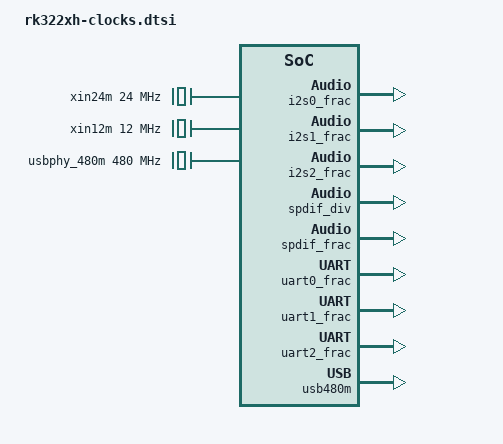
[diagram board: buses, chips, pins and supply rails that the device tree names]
/*
 * Copyright (C) 2014-2015 ROCKCHIP, Inc.
 *
 * This program is free software; you can redistribute it and/or modify
 * it under the terms of the GNU General Public License as published by
 * the Free Software Foundation; either version 2 of the License, or
 * (at your option) any later version.
 *
 * This program is distributed in the hope that it will be useful,
 * but WITHOUT ANY WARRANTY; without even the implied warranty of
 * MERCHANTABILITY or FITNESS FOR A PARTICULAR PURPOSE.  See the
 * GNU General Public License for more details.
 */
#include <dt-bindings/clock/rockchip,rk322xh.h>

/{
	clocks {
		compatible = "rockchip,rk-clocks";
		rockchip,grf = <&grf>;
		#address-cells = <2>;
		#size-cells = <2>;
		ranges;

		fixed_rate_cons {
			compatible = "rockchip,rk-fixed-rate-cons";

			xin24m: xin24m {
				compatible = "rockchip,rk-fixed-clock";
				clock-output-names = "xin24m";
				clock-frequency = <24000000>;
				#clock-cells = <0>;
			};

			xin12m: xin12m {
				compatible = "rockchip,rk-fixed-clock";
				clocks = <&xin24m>;
				clock-output-names = "xin12m";
				clock-frequency = <12000000>;
				#clock-cells = <0>;
			};

			hdmiphy_out: hdmiphy_out {
				compatible = "rockchip,rk-fixed-clock";
				clock-output-names = "hdmiphy_out";
				clock-frequency = <594000000>;
				#clock-cells = <0>;
			};

			usbphy_480m: usbphy_480m {
				compatible = "rockchip,rk-fixed-clock";
				clock-output-names = "usbphy_480m";
				clock-frequency = <480000000>;
				#clock-cells = <0>;
			};

			jtag_clkin: jtag_clkin {
				compatible = "rockchip,rk-fixed-clock";
				clock-output-names = "jtag_clkin";
				clock-frequency = <0>;
				#clock-cells = <0>;
			};

			dummy: dummy {
				compatible = "rockchip,rk-fixed-clock";
				clock-output-names = "dummy";
				clock-frequency = <0>;
				#clock-cells = <0>;
			};

			gmac_clkin: gmac_clkin {
				compatible = "rockchip,rk-fixed-clock";
				clock-output-names = "gmac_clkin";
				clock-frequency = <0>;
				#clock-cells = <0>;
			};

			phy_50m_out: phy_50m_out {
				compatible = "rockchip,rk-fixed-clock";
				clock-output-names = "phy_50m_out";
				clock-frequency = <0>;
				#clock-cells = <0>;
			};

			phy_rx_out: phy_rx_out {
				compatible = "rockchip,rk-fixed-clock";
				clock-output-names = "phy_rx_out";
				clock-frequency = <0>;
				#clock-cells = <0>;
			};

			phy_tx_out: phy_tx_out {
				compatible = "rockchip,rk-fixed-clock";
				clock-output-names = "phy_tx_out";
				clock-frequency = <0>;
				#clock-cells = <0>;
			};

			ext_gpio3a2: ext_gpio3a2 {
				compatible = "rockchip,rk-fixed-clock";
				clock-output-names = "ext_gpio3a2";
				clock-frequency = <0>;
				#clock-cells = <0>;
			};

			i2s1_clkin: i2s1_clkin {
				compatible = "rockchip,rk-fixed-clock";
				clock-output-names = "i2s1_clkin";
				clock-frequency = <0>;
				#clock-cells = <0>;
			};

			i2s2_clkin: i2s2_clkin {
				compatible = "rockchip,rk-fixed-clock";
				clock-output-names = "i2s2_clkin";
				clock-frequency = <0>;
				#clock-cells = <0>;
			};

		};

		fixed_factor_cons {
			compatible = "rockchip,rk-fixed-factor-cons";

			hclk_rkvdec: hclk_rkvdec {
				compatible = "rockchip,rk-fixed-factor-clock";
				clocks = <&aclk_rkvdec>;
				clock-output-names = "hclk_rkvdec";
				clock-div = <4>;
				clock-mult = <1>;
				#clock-cells = <0>;
			};

			hclk_vpu: hclk_vpu {
				compatible = "rockchip,rk-fixed-factor-clock";
				clocks = <&aclk_vpu>;
				clock-output-names = "hclk_vpu";
				clock-div = <4>;
				clock-mult = <1>;
				#clock-cells = <0>;
			};

			hclk_rkvenc: hclk_rkvenc {
				compatible = "rockchip,rk-fixed-factor-clock";
				clocks = <&aclk_rkvenc>;
				clock-output-names = "hclk_rkvenc";
				clock-div = <4>;
				clock-mult = <1>;
				#clock-cells = <0>;
			};

		};

		clock_regs {
			compatible = "rockchip,rk-clock-regs";
			#address-cells = <1>;
			#size-cells = <1>;
			ranges = <0x0 0x0 0xff440000 0x1000>;
			reg = <0x0 0xff440000 0x0 0x1000>;

			/* PLL control regs */
			pll_cons {
				compatible = "rockchip,rk-pll-cons";
				#address-cells = <1>;
				#size-cells = <1>;
				ranges;

				clk_apll: pll-clk@0000 {
					compatible = "rockchip,rk3188-pll-clk";
					reg = <0x0000 0x10>;
					mode-reg = <0x80 0>;
					status-reg = <0x04 10>;
					clocks = <&xin24m>;
					clock-output-names = "clk_apll";
					rockchip,pll-type = <CLK_PLL_312XPLUS>;
					#clock-cells = <0>;
					#clock-init-cells = <1>;
				};

				clk_dpll: pll-clk@0020 {
					compatible = "rockchip,rk3188-pll-clk";
					reg = <0x0020 0x10>;
					mode-reg = <0x80 4>;
					status-reg = <0x24 10>;
					clocks = <&xin24m>;
					clock-output-names = "clk_dpll";
					rockchip,pll-type = <CLK_PLL_3036PLUS_AUTO>;
					#clock-cells = <0>;
				};

				clk_cpll: pll-clk@0040 {
					compatible = "rockchip,rk3188-pll-clk";
					reg = <0x0040 0x1c>;
					mode-reg = <0x80 8>;
					status-reg = <0x44 10>;
					clocks = <&xin24m>;
					clock-output-names = "clk_cpll";
					rockchip,pll-type = <CLK_PLL_3036PLUS_AUTO>;
					#clock-cells = <0>;
					#clock-init-cells = <1>;
				};

				clk_gpll: pll-clk@0060 {
					compatible = "rockchip,rk3188-pll-clk";
					reg = <0x0060 0x1c>;
					mode-reg = <0x80 12>;
					status-reg = <0x64 10>;
					clocks = <&xin24m>;
					clock-output-names = "clk_gpll";
					rockchip,pll-type = <CLK_PLL_312XPLUS>;
					#clock-cells = <0>;
					#clock-init-cells = <1>;
				};

				clk_npll: pll-clk@00a0 {
					compatible = "rockchip,rk3188-pll-clk";
					reg = <0x00a0 0x10>;
					mode-reg = <0x80 1>;
					status-reg = <0xa4 10>;
					clocks = <&xin24m>;
					clock-output-names = "clk_npll";
					rockchip,pll-type = <CLK_PLL_322XH_APLL>;
					#clock-cells = <0>;
					#clock-init-cells = <1>;
				};
			};

			/* Select control regs */
			clk_sel_cons {
				compatible = "rockchip,rk-sel-cons";
				#address-cells = <1>;
				#size-cells = <1>;
				ranges;

				clk_sel_con0: sel-con@0100 {
					compatible = "rockchip,rk3188-selcon";
					reg = <0x0100 0x4>;
					#address-cells = <1>;
					#size-cells = <1>;

					clk_core_div: clk_core_div {
						compatible = "rockchip,rk3188-div-con";
						rockchip,bits = <0 5>;
						clocks = <&clk_core>;
						clock-output-names = "clk_core";
						rockchip,div-type = <CLK_DIVIDER_PLUS_ONE>;
						#clock-cells = <0>;
						rockchip,clkops-idx = <CLKOPS_RATE_CORE>;
						rockchip,flags = <(CLK_GET_RATE_NOCACHE |
									CLK_SET_RATE_NO_REPARENT)>;
					};

					/* 5 reserved */

					clk_core: clk_core_mux {
						compatible = "rockchip,rk3188-mux-con";
						rockchip,bits = <6 2>;
						clocks = <&clk_apll>, <&clk_gpll>, <&clk_dpll>, <&clk_npll>;
						clock-output-names = "clk_core";
						#clock-cells = <0>;
						#clock-init-cells = <1>;
					};

					aclk_bus: aclk_bus_div {
						compatible = "rockchip,rk3188-div-con";
						rockchip,bits = <8 5>;
						clocks = <&aclk_bus_mux>;
						clock-output-names = "aclk_bus";
						rockchip,div-type = <CLK_DIVIDER_PLUS_ONE>;
						#clock-cells = <0>;
						#clock-init-cells = <1>;
						rockchip,clkops-idx = <CLKOPS_RATE_MUX_DIV>;
						rockchip,flags = <CLK_SET_RATE_PARENT_IN_ORDER>;
					};

					aclk_bus_mux: aclk_bus_mux {
						compatible = "rockchip,rk3188-mux-con";
						rockchip,bits = <13 2>;
						clocks = <&clk_cpll>, <&clk_gpll>, <&dummy>;
						clock-output-names = "aclk_bus";
						#clock-cells = <0>;
						#clock-init-cells = <1>;
					};

					/* 15 reserved */
				};

				clk_sel_con1: sel-con@0104 {
					compatible = "rockchip,rk3188-selcon";
					reg = <0x0104 0x4>;
					#address-cells = <1>;
					#size-cells = <1>;

					pclk_dbg:  pclk_dbg_div {
						compatible = "rockchip,rk3188-div-con";
						rockchip,bits = <0 4>;
						clocks = <&clk_core>;
						clock-output-names = "pclk_dbg";
						rockchip,div-type = <CLK_DIVIDER_PLUS_ONE>;
						#clock-cells = <0>;
						rockchip,clkops-idx = <CLKOPS_RATE_CORE_CHILD>;
					};

					aclk_core: aclk_core_div {
						compatible = "rockchip,rk3188-div-con";
						rockchip,bits = <4 3>;
						clocks = <&clk_core>;
						clock-output-names = "aclk_core";
						rockchip,div-type = <CLK_DIVIDER_PLUS_ONE>;
						#clock-cells = <0>;
						rockchip,clkops-idx = <CLKOPS_RATE_CORE_CHILD>;
					};

					/* 7 reserved */

					hclk_bus: hclk_bus_div {
						compatible = "rockchip,rk3188-div-con";
						rockchip,bits = <8 2>;
						clocks = <&aclk_bus>;
						clock-output-names = "hclk_bus";
						rockchip,div-type = <CLK_DIVIDER_PLUS_ONE>;
						#clock-cells = <0>;
						#clock-init-cells = <1>;
					};

					/* 11:10 reserved */

					pclk_bus: pclk_bus_div {
						compatible = "rockchip,rk3188-div-con";
						rockchip,bits = <12 3>;
						clocks = <&aclk_bus>;
						clock-output-names = "pclk_bus";
						rockchip,div-type = <CLK_DIVIDER_PLUS_ONE>;
						#clock-cells = <0>;
						#clock-init-cells = <1>;
					};

					/* 15 reserved */
				};

				clk_sel_con2: sel-con@0108 {
					compatible = "rockchip,rk3188-selcon";
					reg = <0x0108 0x4>;
					#address-cells = <1>;
					#size-cells = <1>;

					testclk_div: testclk_div {
						compatible = "rockchip,rk3188-div-con";
						rockchip,bits = <0 5>;
						clocks = <&testclk>;
						clock-output-names = "testclk";
						rockchip,div-type = <CLK_DIVIDER_PLUS_ONE>;
						#clock-cells = <0>;
						#clock-init-cells = <1>;
						rockchip,clkops-idx = <CLKOPS_RATE_MUX_DIV>;
					};

					/* 7:5 reserved */

					clk_24m: clk_24m_div {
						compatible = "rockchip,rk3188-div-con";
						rockchip,bits = <8 5>;
						clocks = <&xin24m>;
						clock-output-names = "clk_24m";
						rockchip,div-type = <CLK_DIVIDER_PLUS_ONE>;
						#clock-cells = <0>;
						#clock-init-cells = <1>;
					};

					/* 15:13: reserved */
				};

				clk_sel_con3: sel-con@010c {
					compatible = "rockchip,rk3188-selcon";
					reg = <0x010c 0x4>;
					#address-cells = <1>;
					#size-cells = <1>;

					clk_ddr_div: clk_ddr_div {
						compatible = "rockchip,rk3188-div-con";
						rockchip,bits = <0 3>;
						clocks = <&clk_ddr>;
						clock-output-names = "clk_ddr";
						rockchip,div-type = <CLK_DIVIDER_USER_DEFINE>;
						rockchip,div-relations =
								<0x0 1
								 0x1 2
								 0x3 4>;
						#clock-cells = <0>;
						rockchip,flags = <(CLK_GET_RATE_NOCACHE |
									CLK_SET_RATE_NO_REPARENT)>;
						rockchip,clkops-idx = <CLKOPS_RATE_DDR_DIV2>;
					};

					/* 7:3 reserved */

					clk_ddr: clk_ddr_pll_mux {
						compatible = "rockchip,rk3188-mux-con";
						rockchip,bits = <8 2>;
						clocks = <&clk_dpll>, <&clk_apll>, <&clk_cpll>;
						clock-output-names = "clk_ddr";
						#clock-cells = <0>;
					};

					/* 15:10 reserved */
				};

				clk_sel_con4: sel-con@0110 {
					compatible = "rockchip,rk3188-selcon";
					reg = <0x0110 0x4>;
					#address-cells = <1>;
					#size-cells = <1>;

					clk_otp_div: clk_otp_div {
						compatible = "rockchip,rk3188-div-con";
						rockchip,bits = <0 6>;
						clocks = <&clk_otp>;
						clock-output-names = "clk_otp";
						rockchip,div-type = <CLK_DIVIDER_PLUS_ONE>;
						#clock-cells = <0>;
						#clock-init-cells = <1>;
						rockchip,clkops-idx = <CLKOPS_RATE_MUX_DIV>;
						rockchip,flags = <CLK_SET_RATE_PARENT_IN_ORDER>;
					};

					clk_otp: clk_otp_mux {
						compatible = "rockchip,rk3188-mux-con";
						rockchip,bits = <6 2>;
						clocks = <&clk_cpll>, <&clk_gpll>, <&xin24m>;
						clock-output-names = "clk_otp";
						#clock-cells = <0>;
						#clock-init-cells = <1>;
					};

					pclk_ddr_div: pclk_ddr_div {
						compatible = "rockchip,rk3188-div-con";
						rockchip,bits = <8 5>;
						clocks = <&pclk_ddr>;
						clock-output-names = "pclk_ddr";
						rockchip,div-type = <CLK_DIVIDER_PLUS_ONE>;
						#clock-cells = <0>;
						#clock-init-cells = <1>;
						rockchip,clkops-idx = <CLKOPS_RATE_MUX_DIV>;
						rockchip,flags = <CLK_SET_RATE_PARENT_IN_ORDER>;
					};

					pclk_ddr: pclk_ddr_mux {
						compatible = "rockchip,rk3188-mux-con";
						rockchip,bits = <13 2>;
						clocks = <&clk_cpll>, <&clk_gpll>, <&dummy>;
						clock-output-names = "pclk_ddr";
						#clock-cells = <0>;
						#clock-init-cells = <1>;
					};

					/* 15 reserved */
				};

				clk_sel_con5: sel-con@0114 {
					compatible = "rockchip,rk3188-selcon";
					reg = <0x0114 0x4>;
					#address-cells = <1>;
					#size-cells = <1>;

					/* 7:0 reserved */

					clk_efuse_div: clk_efuse_div {
						compatible = "rockchip,rk3188-div-con";
						rockchip,bits = <8 5>;
						clocks = <&clk_efuse>;
						clock-output-names = "clk_efuse";
						rockchip,div-type = <CLK_DIVIDER_PLUS_ONE>;
						#clock-cells = <0>;
						#clock-init-cells = <1>;
						rockchip,clkops-idx = <CLKOPS_RATE_MUX_DIV>;
						rockchip,flags = <CLK_SET_RATE_PARENT_IN_ORDER>;
					};

					/* 14:13 reserved */

					clk_efuse: clk_efuse_mux {
						compatible = "rockchip,rk3188-mux-con";
						rockchip,bits = <14 2>;
						clocks = <&clk_cpll>, <&clk_gpll>, <&xin24m>;
						clock-output-names = "clk_efuse";
						#clock-cells = <0>;
						#clock-init-cells = <1>;
					};
				};

				clk_sel_con6: sel-con@0118 {
					compatible = "rockchip,rk3188-selcon";
					reg = <0x0118 0x4>;
					#address-cells = <1>;
					#size-cells = <1>;

					clk_i2s0_pll_div: clk_i2s0_pll_div {
						compatible = "rockchip,rk3188-div-con";
						rockchip,bits = <0 7>;
						clocks = <&clk_i2s0_pll>;
						clock-output-names = "clk_i2s0_pll";
						rockchip,div-type = <CLK_DIVIDER_PLUS_ONE>;
						#clock-cells = <0>;
						rockchip,clkops-idx =
							<CLKOPS_RATE_MUX_DIV>;
						rockchip,flags = <(CLK_SET_RATE_NO_REPARENT | CLK_SET_RATE_PARENT_IN_ORDER)>;
					};

					/* 7: reserved */

					clk_i2s0: clk_i2s0_mux {
						compatible = "rockchip,rk3188-mux-con";
						rockchip,bits = <8 2>;
						clocks = <&clk_i2s0_pll_div>, <&i2s0_frac>, <&xin12m>, <&xin12m>;
						clock-output-names = "clk_i2s0";
						#clock-cells = <0>;
						rockchip,clkops-idx =
							<CLKOPS_RATE_RK3288_I2S>;
						rockchip,flags = <CLK_SET_RATE_PARENT>;
					};

					/* 14:10: reserved */

					clk_i2s0_pll: i2s0_pll_mux {
						compatible = "rockchip,rk3188-mux-con";
						rockchip,bits = <15 1>;
						clocks = <&clk_cpll>,<&clk_gpll>;
						clock-output-names = "clk_i2s0_pll";
						#clock-cells = <0>;
						#clock-init-cells = <1>;
					};
				};

				clk_sel_con7: sel-con@011c {
					compatible = "rockchip,rk3188-selcon";
					reg = <0x011c 0x4>;
					#address-cells = <1>;
					#size-cells = <1>;

					i2s0_frac: i2s0_frac {
						compatible = "rockchip,rk3188-frac-con";
						clocks = <&clk_i2s0_pll_div>;
						clock-output-names = "i2s0_frac";
						/* numerator	denominator */
						rockchip,bits = <0 32>;
						rockchip,clkops-idx =
							<CLKOPS_RATE_FRAC>;
						#clock-cells = <0>;
					};
				};

				clk_sel_con8: sel-con@0120 {
					compatible = "rockchip,rk3188-selcon";
					reg = <0x0120 0x4>;
					#address-cells = <1>;
					#size-cells = <1>;

					clk_i2s1_pll_div: clk_i2s1_pll_div {
						compatible = "rockchip,rk3188-div-con";
						rockchip,bits = <0 7>;
						clocks = <&clk_i2s1_pll>;
						clock-output-names = "clk_i2s1_pll";
						rockchip,div-type = <CLK_DIVIDER_PLUS_ONE>;
						#clock-cells = <0>;
						rockchip,clkops-idx =
							<CLKOPS_RATE_MUX_DIV>;
						rockchip,flags = <(CLK_SET_RATE_NO_REPARENT | CLK_SET_RATE_PARENT_IN_ORDER)>;
					};

					/* 7: reserved */

					clk_i2s1: clk_i2s1_mux {
						compatible = "rockchip,rk3188-mux-con";
						rockchip,bits = <8 2>;
						clocks = <&clk_i2s1_pll_div>, <&i2s1_frac>, <&i2s1_clkin>, <&xin12m>;
						clock-output-names = "clk_i2s1";
						#clock-cells = <0>;
						rockchip,clkops-idx =
							<CLKOPS_RATE_RK3288_I2S>;
						rockchip,flags = <CLK_SET_RATE_PARENT>;
					};

					/* 11:10: reserved */

					clk_i2s1_out: clk_i2s1_out_mux {
						compatible = "rockchip,rk3188-mux-con";
						rockchip,bits = <12 1>;
						clocks = <&clk_i2s1>, <&xin12m>;
						clock-output-names = "clk_i2s1_out";
						#clock-cells = <0>;
					};

					/* 14:13: reserved */

					clk_i2s1_pll: i2s1_pll_mux {
						compatible = "rockchip,rk3188-mux-con";
						rockchip,bits = <15 1>;
						clocks = <&clk_cpll>,<&clk_gpll>;
						clock-output-names = "clk_i2s1_pll";
						#clock-cells = <0>;
						#clock-init-cells = <1>;
					};
				};

				clk_sel_con9: sel-con@0124 {
					compatible = "rockchip,rk3188-selcon";
					reg = <0x0124 0x4>;
					#address-cells = <1>;
					#size-cells = <1>;

					i2s1_frac: i2s1_frac {
						compatible = "rockchip,rk3188-frac-con";
						clocks = <&clk_i2s1_pll_div>;
						clock-output-names = "i2s1_frac";
						/* numerator	denominator */
						rockchip,bits = <0 32>;
						rockchip,clkops-idx =
							<CLKOPS_RATE_FRAC>;
						#clock-cells = <0>;
					};
				};

				clk_sel_con10: sel-con@0128 {
					compatible = "rockchip,rk3188-selcon";
					reg = <0x0128 0x4>;
					#address-cells = <1>;
					#size-cells = <1>;

					clk_i2s2_pll_div: clk_i2s2_pll_div {
						compatible = "rockchip,rk3188-div-con";
						rockchip,bits = <0 7>;
						clocks = <&clk_i2s2_pll>;
						clock-output-names = "clk_i2s2_pll";
						rockchip,div-type = <CLK_DIVIDER_PLUS_ONE>;
						#clock-cells = <0>;
						rockchip,clkops-idx =
							<CLKOPS_RATE_MUX_DIV>;
						rockchip,flags = <(CLK_SET_RATE_NO_REPARENT | CLK_SET_RATE_PARENT_IN_ORDER)>;
					};

					/* 7: reserved */

					clk_i2s2: clk_i2s2_mux {
						compatible = "rockchip,rk3188-mux-con";
						rockchip,bits = <8 2>;
						clocks = <&clk_i2s2_pll_div>, <&i2s2_frac>, <&i2s2_clkin>, <&xin12m>;
						clock-output-names = "clk_i2s2";
						#clock-cells = <0>;
						rockchip,clkops-idx =
							<CLKOPS_RATE_RK3288_I2S>;
						rockchip,flags = <CLK_SET_RATE_PARENT>;
					};

					/* 11:10: reserved */

					clk_i2s2_out: clk_i2s2_out_mux {
						compatible = "rockchip,rk3188-mux-con";
						rockchip,bits = <12 1>;
						clocks = <&clk_i2s2>, <&xin12m>;
						clock-output-names = "clk_i2s2_out";
						#clock-cells = <0>;
					};

					/* 14:13: reserved */

					clk_i2s2_pll: i2s2_pll_mux {
						compatible = "rockchip,rk3188-mux-con";
						rockchip,bits = <15 1>;
						clocks = <&clk_cpll>,<&clk_gpll>;
						clock-output-names = "clk_i2s2_pll";
						#clock-cells = <0>;
						#clock-init-cells = <1>;
					};
				};

				clk_sel_con11: sel-con@012c {
					compatible = "rockchip,rk3188-selcon";
					reg = <0x012c 0x4>;
					#address-cells = <1>;
					#size-cells = <1>;

					i2s2_frac: i2s2_frac {
						compatible = "rockchip,rk3188-frac-con";
						clocks = <&clk_i2s2_pll_div>;
						clock-output-names = "i2s2_frac";
						/* numerator	denominator */
						rockchip,bits = <0 32>;
						rockchip,clkops-idx =
							<CLKOPS_RATE_FRAC>;
						#clock-cells = <0>;
					};
				};

				clk_sel_con12: sel-con@0130 {
					compatible = "rockchip,rk3188-selcon";
					reg = <0x0130 0x4>;
					#address-cells = <1>;
					#size-cells = <1>;

					spdif_div: spdif_div {
						compatible = "rockchip,rk3188-div-con";
						rockchip,bits = <0 7>;
						clocks = <&clk_spdif_pll>;
						clock-output-names = "clk_spdif_pll";
						rockchip,div-type = <CLK_DIVIDER_PLUS_ONE>;
						#clock-cells = <0>;
						rockchip,clkops-idx =
							<CLKOPS_RATE_MUX_DIV>;
						rockchip,flags = <(CLK_SET_RATE_NO_REPARENT | CLK_SET_RATE_PARENT_IN_ORDER)>;
					};

					/* 7 reserved */

					clk_spdif: spdif_mux {
						compatible = "rockchip,rk3188-mux-con";
						rockchip,bits = <8 2>;
						clocks = <&spdif_div>, <&spdif_frac>, <&xin12m>, <&xin12m>;
						clock-output-names = "clk_spdif";
						#clock-cells = <0>;
						rockchip,clkops-idx =
							<CLKOPS_RATE_RK3288_I2S>;
						rockchip,flags = <CLK_SET_RATE_PARENT>;
					};

					/* 14:10 reserved */

					clk_spdif_pll: spdif_pll_mux {
						compatible = "rockchip,rk3188-mux-con";
						rockchip,bits = <15 1>;
						clocks = <&clk_cpll>,<&clk_gpll>;
						clock-output-names = "clk_spdif_pll";
						#clock-cells = <0>;
						#clock-init-cells = <1>;
					};
				};

				clk_sel_con13: sel-con@0134 {
					compatible = "rockchip,rk3188-selcon";
					reg = <0x0134 0x4>;
					#address-cells = <1>;
					#size-cells = <1>;

					spdif_frac: spdif_frac {
						compatible = "rockchip,rk3188-frac-con";
						clocks = <&spdif_div>;
						clock-output-names = "spdif_frac";
						/* numerator	denominator */
						rockchip,bits = <0 32>;
						rockchip,clkops-idx =
							<CLKOPS_RATE_FRAC>;
						#clock-cells = <0>;
					};
				};

				clk_sel_con14: sel-con@0138 {
					compatible = "rockchip,rk3188-selcon";
					reg = <0x0138 0x4>;
					#address-cells = <1>;
					#size-cells = <1>;

					clk_uart0_pll_div: clk_uart0_pll_div {
						compatible = "rockchip,rk3188-div-con";
						rockchip,bits = <0 7>;
						clocks = <&clk_uart0_pll>;
						clock-output-names = "clk_uart0_pll";
						rockchip,div-type = <CLK_DIVIDER_PLUS_ONE>;
						#clock-cells = <0>;
						rockchip,flags = <CLK_SET_RATE_PARENT_IN_ORDER>;
					};

					/* 7 reserved */

					clk_uart0: clk_uart0_mux {
						compatible = "rockchip,rk3188-mux-con";
						rockchip,bits = <8 2>;
						clocks = <&clk_uart0_pll_div>, <&uart0_frac>, <&xin24m>;
						clock-output-names = "clk_uart0";
						#clock-cells = <0>;
						rockchip,clkops-idx =
							<CLKOPS_RATE_RK3288_I2S>;
						rockchip,flags = <CLK_SET_RATE_PARENT>;
						#clock-init-cells = <1>;
					};

					/* 11:10 reserved */

					clk_uart0_pll: clk_uart0_pll_mux {
						compatible = "rockchip,rk3188-mux-con";
						rockchip,bits = <12 2>;
						clocks = <&clk_cpll>, <&clk_gpll>, <&usb480m>;
						clock-output-names = "clk_uart0_pll";
						#clock-cells = <0>;
						#clock-init-cells = <1>;
					};

					/* 15:14 reserved */
				};

				clk_sel_con15: sel-con@013c {
					compatible = "rockchip,rk3188-selcon";
					reg = <0x013c 0x4>;
					#address-cells = <1>;
					#size-cells = <1>;

					uart0_frac: uart0_frac {
						compatible = "rockchip,rk3188-frac-con";
						clocks = <&clk_uart0_pll_div>;
						clock-output-names = "uart0_frac";
						/* numerator	denominator */
						rockchip,bits = <0 32>;
						rockchip,clkops-idx =
							<CLKOPS_RATE_FRAC>;
						#clock-cells = <0>;
					};
				};

				clk_sel_con16: sel-con@0140 {
					compatible = "rockchip,rk3188-selcon";
					reg = <0x0140 0x4>;
					#address-cells = <1>;
					#size-cells = <1>;

					clk_uart1_pll_div: clk_uart1_pll_div {
						compatible = "rockchip,rk3188-div-con";
						rockchip,bits = <0 7>;
						clocks = <&clk_uart1_pll>;
						clock-output-names = "clk_uart1_pll";
						rockchip,div-type = <CLK_DIVIDER_PLUS_ONE>;
						#clock-cells = <0>;
						rockchip,flags = <CLK_SET_RATE_PARENT_IN_ORDER>;
					};

					/* 7 reserved */

					clk_uart1: clk_uart1_mux {
						compatible = "rockchip,rk3188-mux-con";
						rockchip,bits = <8 2>;
						clocks = <&clk_uart1_pll_div>, <&uart1_frac>, <&xin24m>;
						clock-output-names = "clk_uart1";
						#clock-cells = <0>;
						rockchip,clkops-idx =
							<CLKOPS_RATE_RK3288_I2S>;
						rockchip,flags = <CLK_SET_RATE_PARENT>;
						#clock-init-cells = <1>;
					};

					/* 11:10 reserved */

					clk_uart1_pll: clk_uart1_pll_mux {
						compatible = "rockchip,rk3188-mux-con";
						rockchip,bits = <12 2>;
						clocks = <&clk_cpll>, <&clk_gpll>, <&usb480m>;
						clock-output-names = "clk_uart1_pll";
						#clock-cells = <0>;
						#clock-init-cells = <1>;
					};

					/* 15:14 reserved */
				};

				clk_sel_con17: sel-con@0144 {
					compatible = "rockchip,rk3188-selcon";
					reg = <0x0144 0x4>;
					#address-cells = <1>;
					#size-cells = <1>;

					uart1_frac: uart1_frac {
						compatible = "rockchip,rk3188-frac-con";
						clocks = <&clk_uart1_pll_div>;
						clock-output-names = "uart1_frac";
						/* numerator	denominator */
						rockchip,bits = <0 32>;
						rockchip,clkops-idx =
							<CLKOPS_RATE_FRAC>;
						#clock-cells = <0>;
					};
				};

				clk_sel_con18: sel-con@0148 {
					compatible = "rockchip,rk3188-selcon";
					reg = <0x0148 0x4>;
					#address-cells = <1>;
					#size-cells = <1>;

					clk_uart2_pll_div: clk_uart2_pll_div {
						compatible = "rockchip,rk3188-div-con";
						rockchip,bits = <0 7>;
						clocks = <&clk_uart2_pll>;
						clock-output-names = "clk_uart2_pll";
						rockchip,div-type = <CLK_DIVIDER_PLUS_ONE>;
						#clock-cells = <0>;
						rockchip,flags = <CLK_SET_RATE_PARENT_IN_ORDER>;
					};

					/* 7 reserved */

					clk_uart2: clk_uart2_mux {
						compatible = "rockchip,rk3188-mux-con";
						rockchip,bits = <8 2>;
						clocks = <&clk_uart2_pll>, <&uart2_frac>, <&xin24m>;
						clock-output-names = "clk_uart2";
						#clock-cells = <0>;
						rockchip,clkops-idx =
							<CLKOPS_RATE_RK3288_I2S>;
						rockchip,flags = <CLK_SET_RATE_PARENT>;
						#clock-init-cells = <1>;
					};

					/* 11:10 reserved */

					clk_uart2_pll: clk_uart2_pll_mux {
						compatible = "rockchip,rk3188-mux-con";
						rockchip,bits = <12 2>;
						clocks = <&clk_cpll>, <&clk_gpll>, <&usb480m>;
						clock-output-names = "clk_uart2_pll";
						#clock-cells = <0>;
						#clock-init-cells = <1>;
					};

					/* 15:14 reserved */
				};

				clk_sel_con19: sel-con@014c {
					compatible = "rockchip,rk3188-selcon";
					reg = <0x014c 0x4>;
					#address-cells = <1>;
					#size-cells = <1>;

					uart2_frac: uart2_frac {
						compatible = "rockchip,rk3188-frac-con";
						clocks = <&clk_uart2_pll_div>;
						clock-output-names = "uart2_frac";
						/* numerator	denominator */
						rockchip,bits = <0 32>;
						rockchip,clkops-idx =
							<CLKOPS_RATE_FRAC>;
						#clock-cells = <0>;
					};
				};

				clk_sel_con20: sel-con@0150 {
					compatible = "rockchip,rk3188-selcon";
					reg = <0x0150 0x4>;
					#address-cells = <1>;
					#size-cells = <1>;

					clk_crypto_div: clk_crypto_div {
						compatible = "rockchip,rk3188-div-con";
						rockchip,bits = <0 5>;
						clocks = <&clk_crypto>;
						clock-output-names = "clk_crypto";
						rockchip,div-type = <CLK_DIVIDER_PLUS_ONE>;
						#clock-cells = <0>;
						#clock-init-cells = <1>;
						rockchip,clkops-idx = <CLKOPS_RATE_MUX_DIV>;
						rockchip,flags = <CLK_SET_RATE_PARENT_IN_ORDER>;
					};

					/* 6:5 reserved */

					clk_crypto: clk_crypto_mux {
						compatible = "rockchip,rk3188-mux-con";
						rockchip,bits = <7 1>;
						clocks = <&clk_cpll>, <&clk_gpll>;
						clock-output-names = "clk_crypto";
						#clock-cells = <0>;
						#clock-init-cells = <1>;
					};

					clk_pdm_div: clk_pdm_div {
						compatible = "rockchip,rk3188-div-con";
						rockchip,bits = <8 5>;
						clocks = <&clk_pdm>;
						clock-output-names = "clk_pdm";
						rockchip,div-type = <CLK_DIVIDER_PLUS_ONE>;
						#clock-cells = <0>;
						#clock-init-cells = <1>;
						rockchip,clkops-idx = <CLKOPS_RATE_MUX_DIV>;
						rockchip,flags = <(CLK_SET_RATE_PARENT |
								  CLK_SET_RATE_NO_REPARENT)>;
					};

					/* 13 reserved */

					clk_pdm: clk_pdm_mux {
						compatible = "rockchip,rk3188-mux-con";
						rockchip,bits = <14 2>;
						clocks = <&dummy>, <&dummy>, <&clk_apll>, <&dummy>;
						clock-output-names = "clk_pdm";
						#clock-cells = <0>;
						#clock-init-cells = <1>;
					};
				};

				clk_sel_con21: sel-con@0154 {
					compatible = "rockchip,rk3188-selcon";
					reg = <0x0154 0x4>;
					#address-cells = <1>;
					#size-cells = <1>;

					/* 7:0 reserved */

					clk_tsp_div: clk_tsp_div {
						compatible = "rockchip,rk3188-div-con";
						rockchip,bits = <8 5>;
						clocks = <&clk_tsp>;
						clock-output-names = "clk_tsp";
						rockchip,div-type = <CLK_DIVIDER_PLUS_ONE>;
						#clock-cells = <0>;
						rockchip,clkops-idx = <CLKOPS_RATE_MUX_DIV>;
					};

					/* 14:13 reserved */

					clk_tsp: clk_tsp_mux {
						compatible = "rockchip,rk3188-mux-con";
						rockchip,bits = <15 1>;
						clocks = <&clk_cpll>, <&clk_gpll>;
						clock-output-names = "clk_tsp";
						#clock-cells = <0>;
					};
				};

				clk_sel_con22: sel-con@0158 {
					compatible = "rockchip,rk3188-selcon";
					reg = <0x0158 0x4>;
					#address-cells = <1>;
					#size-cells = <1>;

					clk_tsadc: clk_tsadc_div {
						compatible = "rockchip,rk3188-div-con";
						rockchip,bits = <0 10>;
						clocks = <&clk_24m>;
						clock-output-names = "clk_tsadc";
						rockchip,div-type = <CLK_DIVIDER_PLUS_ONE>;
						#clock-cells = <0>;
					};

					/* 15:10 reserved */
				};

				clk_sel_con23: sel-con@015c {
					compatible = "rockchip,rk3188-selcon";
					reg = <0x015c 0x4>;
					#address-cells = <1>;
					#size-cells = <1>;

					clk_saradc: clk_saradc_div {
						compatible = "rockchip,rk3188-div-con";
						rockchip,bits = <0 10>;
						clocks = <&clk_24m>;
						clock-output-names = "clk_saradc";
						rockchip,div-type = <CLK_DIVIDER_PLUS_ONE>;
						#clock-cells = <0>;
					};

					/* 15:10 reserved */
				};

				clk_sel_con24: sel-con@0160 {
					compatible = "rockchip,rk3188-selcon";
					reg = <0x0160 0x4>;
					#address-cells = <1>;
					#size-cells = <1>;

					clk_spi_div: clk_spi_div {
						compatible = "rockchip,rk3188-div-con";
						rockchip,bits = <0 7>;
						clocks = <&clk_spi>;
						clock-output-names = "clk_spi";
						rockchip,div-type = <CLK_DIVIDER_PLUS_ONE>;
						#clock-cells = <0>;
						#clock-init-cells = <1>;
						rockchip,clkops-idx = <CLKOPS_RATE_MUX_DIV>;
						rockchip,flags = <CLK_SET_RATE_PARENT_IN_ORDER>;
					};

					clk_spi: clk_spi_mux {
						compatible = "rockchip,rk3188-mux-con";
						rockchip,bits = <7 1>;
						clocks = <&clk_cpll>, <&clk_gpll>;
						clock-output-names = "clk_spi";
						#clock-cells = <0>;
						#clock-init-cells = <1>;
					};

					clk_pwm_div: clk_pwm_div {
						compatible = "rockchip,rk3188-div-con";
						rockchip,bits = <8 7>;
						clocks = <&clk_pwm>;
						clock-output-names = "clk_pwm";
						rockchip,div-type = <CLK_DIVIDER_PLUS_ONE>;
						#clock-cells = <0>;
						#clock-init-cells = <1>;
						rockchip,clkops-idx = <CLKOPS_RATE_MUX_DIV>;
						rockchip,flags = <CLK_SET_RATE_PARENT_IN_ORDER>;
					};

					clk_pwm: clk_pwm_mux {
						compatible = "rockchip,rk3188-mux-con";
						rockchip,bits = <15 1>;
						clocks = <&clk_cpll>, <&clk_gpll>;
						clock-output-names = "clk_pwm";
						#clock-cells = <0>;
						#clock-init-cells = <1>;
					};
				};

				clk_sel_con25: sel-con@0164 {
					compatible = "rockchip,rk3188-selcon";
					reg = <0x0164 0x4>;
					#address-cells = <1>;
					#size-cells = <1>;

					aclk_gmac_div: aclk_gmac_div {
						compatible = "rockchip,rk3188-div-con";
						rockchip,bits = <0 5>;
						clocks = <&aclk_gmac>;
						clock-output-names = "aclk_gmac";
						rockchip,div-type = <CLK_DIVIDER_PLUS_ONE>;
						#clock-cells = <0>;
						#clock-init-cells = <1>;
						rockchip,clkops-idx = <CLKOPS_RATE_MUX_DIV>;
						rockchip,flags = <CLK_SET_RATE_PARENT_IN_ORDER>;
					};

					/* 5 reserved */

					aclk_gmac: aclk_gmac_mux {
						compatible = "rockchip,rk3188-mux-con";
						rockchip,bits = <6 2>;
						clocks = <&clk_cpll>, <&clk_gpll>, <&dummy>;
						clock-output-names = "aclk_gmac";
						#clock-cells = <0>;
						#clock-init-cells = <1>;
					};

					pclk_gmac: pclk_gmac_div {
						compatible = "rockchip,rk3188-div-con";
						rockchip,bits = <8 3>;
						clocks = <&aclk_gmac>;
						clock-output-names = "pclk_gmac";
						rockchip,div-type = <CLK_DIVIDER_PLUS_ONE>;
						#clock-cells = <0>;
						#clock-init-cells = <1>;
					};

					/* 15:11 reserved */
				};

				clk_sel_con26: sel-con@0168 {
					compatible = "rockchip,rk3188-selcon";
					reg = <0x0168 0x4>;
					#address-cells = <1>;
					#size-cells = <1>;

					clk_mac2phy_div: clk_mac2phy_div {
						compatible = "rockchip,rk3188-div-con";
						rockchip,bits = <0 5>;
						clocks = <&clk_mac2phy>;
						clock-output-names = "clk_mac2phy";
						rockchip,div-type = <CLK_DIVIDER_PLUS_ONE>;
						#clock-cells = <0>;
						#clock-init-cells = <1>;
						rockchip,clkops-idx = <CLKOPS_RATE_MUX_DIV>;
					};

					/* 6:5 reserved */

					clk_mac2phy: clk_mac2phy_mux {
						compatible = "rockchip,rk3188-mux-con";
						rockchip,bits = <7 1>;
						clocks = <&clk_cpll>, <&clk_gpll>;
						clock-output-names = "clk_mac2phy";
						#clock-cells = <0>;
						#clock-init-cells = <1>;
					};

					clk_mac2phy_out: clk_mac2phy_out_div {
						compatible = "rockchip,rk3188-div-con";
						rockchip,bits = <8 2>;
						clocks = <&clk_mac2phy_div>;
						clock-output-names = "clk_mac2phy_out";
						rockchip,div-type = <CLK_DIVIDER_PLUS_ONE>;
						#clock-cells = <0>;
						#clock-init-cells = <1>;
					};

					/*15:10 reserved */
				};

				clk_sel_con27: sel-con@016c {
					compatible = "rockchip,rk3188-selcon";
					reg = <0x016c 0x4>;
					#address-cells = <1>;
					#size-cells = <1>;

					clk_mac2io_div: clk_mac2io_div {
						compatible = "rockchip,rk3188-div-con";
						rockchip,bits = <0 5>;
						clocks = <&clk_mac2io>;
						clock-output-names = "clk_mac2io";
						rockchip,div-type = <CLK_DIVIDER_PLUS_ONE>;
						#clock-cells = <0>;
						#clock-init-cells = <1>;
						rockchip,clkops-idx = <CLKOPS_RATE_MUX_DIV>;
					};

					/* 6:5 reserved */

					clk_mac2io: clk_mac2io_mux {
						compatible = "rockchip,rk3188-mux-con";
						rockchip,bits = <7 1>;
						clocks = <&clk_cpll>, <&clk_gpll>;
						clock-output-names = "clk_mac2io";
						#clock-cells = <0>;
						#clock-init-cells = <1>;
					};

					clk_mac2io_out_div: clk_mac2io_out_div {
						compatible = "rockchip,rk3188-div-con";
						rockchip,bits = <8 2>;
						clocks = <&clk_mac2io_out>;
						clock-output-names = "clk_mac2io_out";
						rockchip,div-type = <CLK_DIVIDER_PLUS_ONE>;
						#clock-cells = <0>;
						#clock-init-cells = <1>;
						rockchip,clkops-idx = <CLKOPS_RATE_MUX_DIV>;
					};

					/*14:13 reserved */

					clk_mac2io_out: clk_mac2io_out_mux {
						compatible = "rockchip,rk3188-mux-con";
						rockchip,bits = <15 1>;
						clocks = <&clk_cpll>, <&clk_gpll>;
						clock-output-names = "clk_mac2io_out";
						#clock-cells = <0>;
						#clock-init-cells = <1>;
					};
				};

				clk_sel_con28: sel-con@0170 {
					compatible = "rockchip,rk3188-selcon";
					reg = <0x0170 0x4>;
					#address-cells = <1>;
					#size-cells = <1>;

					aclk_peri_div: aclk_peri_div {
						compatible = "rockchip,rk3188-div-con";
						rockchip,bits = <0 5>;
						clocks = <&aclk_peri>;
						clock-output-names = "aclk_peri";
						rockchip,div-type = <CLK_DIVIDER_PLUS_ONE>;
						#clock-cells = <0>;
						#clock-init-cells = <1>;
						rockchip,clkops-idx = <CLKOPS_RATE_MUX_DIV>;
						rockchip,flags = <CLK_SET_RATE_PARENT_IN_ORDER>;
					};

					/* 5: reserved */

					aclk_peri: aclk_peri_mux {
						compatible = "rockchip,rk3188-mux-con";
						rockchip,bits = <6 2>;
						clocks = <&clk_cpll>, <&clk_gpll>, <&dummy>;
						clock-output-names = "aclk_peri";
						#clock-cells = <0>;
						#clock-init-cells = <1>;
					};

					/* 15:8 reserved */
				};

				clk_sel_con29: sel-con@0174 {
					compatible = "rockchip,rk3188-selcon";
					reg = <0x0174 0x4>;
					#address-cells = <1>;
					#size-cells = <1>;

					hclk_peri: hclk_peri_div {
						compatible = "rockchip,rk3188-div-con";
						rockchip,bits = <0 2>;
						clocks = <&aclk_peri>;
						clock-output-names = "hclk_peri";
						rockchip,div-type = <CLK_DIVIDER_USER_DEFINE>;
						rockchip,div-relations =
								<0x0 1
								 0x1 2
								 0x2 4>;
						#clock-cells = <0>;
						#clock-init-cells = <1>;
					};

					/* 3:2 reserved */

					pclk_peri: pclk_peri_div {
						compatible = "rockchip,rk3188-div-con";
						rockchip,bits = <4 2>;
						clocks = <&aclk_peri>;
						clock-output-names = "pclk_peri";
						rockchip,div-type = <CLK_DIVIDER_USER_DEFINE>;
						rockchip,div-relations =
								<0x0 1
								 0x1 2
								 0x2 4
								 0x3 8>;
						#clock-cells = <0>;
						#clock-init-cells = <1>;
					};

					/* 15:7 reserved */
				};

				clk_sel_con30: sel-con@0178 {
					compatible = "rockchip,rk3188-selcon";
					reg = <0x0178 0x4>;
					#address-cells = <1>;
					#size-cells = <1>;

					clk_sdmmc_div: clk_sdmmc_div {
						compatible = "rockchip,rk3188-div-con";
						rockchip,bits = <0 8>;
						clocks = <&clk_sdmmc>;
						clock-output-names = "clk_sdmmc";
						rockchip,div-type = <CLK_DIVIDER_PLUS_ONE>;
						#clock-cells = <0>;
						rockchip,clkops-idx =
							<CLKOPS_RATE_MUX_EVENDIV>;
						rockchip,flags = <CLK_SET_RATE_PARENT_IN_ORDER>;
					};

					clk_sdmmc: clk_sdmmc_mux {
						compatible = "rockchip,rk3188-mux-con";
						rockchip,bits = <8 2>;
						clocks = <&clk_cpll>,<&clk_gpll>,<&xin24m>,<&usb480m>;
						clock-output-names = "clk_sdmmc";
						#clock-cells = <0>;
						#clock-init-cells = <1>;
					};

					/* 15:10 reserved */
				};

				clk_sel_con31: sel-con@017c {
					compatible = "rockchip,rk3188-selcon";
					reg = <0x017c 0x4>;
					#address-cells = <1>;
					#size-cells = <1>;

					clk_sdio_div: clk_sdio_div {
						compatible = "rockchip,rk3188-div-con";
						rockchip,bits = <0 8>;
						clocks = <&clk_sdio>;
						clock-output-names = "clk_sdio";
						rockchip,div-type = <CLK_DIVIDER_PLUS_ONE>;
						#clock-cells = <0>;
						rockchip,clkops-idx =
							<CLKOPS_RATE_MUX_EVENDIV>;
						rockchip,flags = <CLK_SET_RATE_PARENT_IN_ORDER>;
					};

					clk_sdio: clk_sdio_mux {
						compatible = "rockchip,rk3188-mux-con";
						rockchip,bits = <8 2>;
						clocks = <&clk_cpll>,<&clk_gpll>,<&xin24m>,<&usb480m>;
						clock-output-names = "clk_sdio";
						#clock-cells = <0>;
						#clock-init-cells = <1>;
					};

					/* 15:10 reserved */
				};

				clk_sel_con32: sel-con@0180 {
					compatible = "rockchip,rk3188-selcon";
					reg = <0x0180 0x4>;
					#address-cells = <1>;
					#size-cells = <1>;

					clk_emmc_div: clk_emmc_div {
						compatible = "rockchip,rk3188-div-con";
						rockchip,bits = <0 8>;
						clocks = <&clk_emmc>;
						clock-output-names = "clk_emmc";
						rockchip,div-type = <CLK_DIVIDER_PLUS_ONE>;
						#clock-cells = <0>;
						rockchip,clkops-idx =
							<CLKOPS_RATE_MUX_EVENDIV>;
						rockchip,flags = <CLK_SET_RATE_PARENT_IN_ORDER>;
					};

					clk_emmc: clk_emmc_mux {
						compatible = "rockchip,rk3188-mux-con";
						rockchip,bits = <8 2>;
						clocks = <&clk_cpll>,<&clk_gpll>,<&xin24m>,<&usb480m>;
						clock-output-names = "clk_emmc";
						#clock-cells = <0>;
						#clock-init-cells = <1>;
					};

					/* 15:10 reserved */
				};

				clk_sel_con33: sel-con@0184 {
					compatible = "rockchip,rk3188-selcon";
					reg = <0x0184 0x4>;
					#address-cells = <1>;
					#size-cells = <1>;

					clk_usb3otg0_s_div: clk_usb3otg0_s_div {
						compatible = "rockchip,rk3188-div-con";
						rockchip,bits = <0 10>;
						clocks = <&clk_usb3otg0_s>;
						clock-output-names = "clk_usb3otg0_s";
						rockchip,div-type = <CLK_DIVIDER_PLUS_ONE>;
						#clock-cells = <0>;
						rockchip,clkops-idx = <CLKOPS_RATE_MUX_DIV>;
						rockchip,flags = <CLK_SET_RATE_PARENT_IN_ORDER>;
					};

					/* 14:10 reserved */

					clk_usb3otg0_s: clk_usb3otg0_s_mux {
						compatible = "rockchip,rk3188-mux-con";
						rockchip,bits = <15 1>;
						clocks = <&xin24m>, <&clk_rtc32k>;
						clock-output-names = "clk_usb3otg0_s";
						#clock-cells = <0>;
						#clock-init-cells = <1>;
					};
				};

				clk_sel_con34: sel-con@0188 {
					compatible = "rockchip,rk3188-selcon";
					reg = <0x0188 0x4>;
					#address-cells = <1>;
					#size-cells = <1>;

					clk_i2c0_div: clk_i2c0_div {
						compatible = "rockchip,rk3188-div-con";
						rockchip,bits = <0 7>;
						clocks = <&clk_i2c0>;
						clock-output-names = "clk_i2c0";
						rockchip,div-type = <CLK_DIVIDER_PLUS_ONE>;
						#clock-cells = <0>;
						rockchip,clkops-idx = <CLKOPS_RATE_MUX_DIV>;
						rockchip,flags = <CLK_SET_RATE_PARENT_IN_ORDER>;
					};

					clk_i2c0: clk_i2c0_mux {
						compatible = "rockchip,rk3188-mux-con";
						rockchip,bits = <7 1>;
						clocks = <&clk_cpll>, <&clk_gpll>;
						clock-output-names = "clk_i2c0";
						#clock-cells = <0>;
						#clock-init-cells = <1>;
					};

					clk_i2c1_div: clk_i2c1_div {
						compatible = "rockchip,rk3188-div-con";
						rockchip,bits = <8 7>;
						clocks = <&clk_i2c1>;
						clock-output-names = "clk_i2c1";
						rockchip,div-type = <CLK_DIVIDER_PLUS_ONE>;
						#clock-cells = <0>;
						rockchip,clkops-idx = <CLKOPS_RATE_MUX_DIV>;
						rockchip,flags = <CLK_SET_RATE_PARENT_IN_ORDER>;
					};

					clk_i2c1: clk_i2c1_mux {
						compatible = "rockchip,rk3188-mux-con";
						rockchip,bits = <15 1>;
						clocks = <&clk_cpll>, <&clk_gpll>;
						clock-output-names = "clk_i2c1";
						#clock-cells = <0>;
						#clock-init-cells = <1>;
					};
				};

				clk_sel_con35: sel-con@018c {
					compatible = "rockchip,rk3188-selcon";
					reg = <0x018c 0x4>;
					#address-cells = <1>;
					#size-cells = <1>;

					clk_i2c2_div: clk_i2c2_div {
						compatible = "rockchip,rk3188-div-con";
						rockchip,bits = <0 7>;
						clocks = <&clk_i2c2>;
						clock-output-names = "clk_i2c2";
						rockchip,div-type = <CLK_DIVIDER_PLUS_ONE>;
						#clock-cells = <0>;
						rockchip,clkops-idx = <CLKOPS_RATE_MUX_DIV>;
						rockchip,flags = <CLK_SET_RATE_PARENT_IN_ORDER>;
					};

					clk_i2c2: clk_i2c2_mux {
						compatible = "rockchip,rk3188-mux-con";
						rockchip,bits = <7 1>;
						clocks = <&clk_cpll>, <&clk_gpll>;
						clock-output-names = "clk_i2c2";
						#clock-cells = <0>;
						#clock-init-cells = <1>;
					};

					clk_i2c3_div: clk_i2c3_div {
						compatible = "rockchip,rk3188-div-con";
						rockchip,bits = <8 7>;
						clocks = <&clk_i2c3>;
						clock-output-names = "clk_i2c3";
						rockchip,div-type = <CLK_DIVIDER_PLUS_ONE>;
						#clock-cells = <0>;
						rockchip,clkops-idx = <CLKOPS_RATE_MUX_DIV>;
						rockchip,flags = <CLK_SET_RATE_PARENT_IN_ORDER>;
					};

					clk_i2c3: clk_i2c3_mux {
						compatible = "rockchip,rk3188-mux-con";
						rockchip,bits = <15 1>;
						clocks = <&clk_cpll>, <&clk_gpll>;
						clock-output-names = "clk_i2c3";
						#clock-cells = <0>;
						#clock-init-cells = <1>;
					};
				};

				clk_sel_con36: sel-con@0190 {
					compatible = "rockchip,rk3188-selcon";
					reg = <0x0190 0x4>;
					#address-cells = <1>;
					#size-cells = <1>;

					clk_rga_div: clk_rga_div {
						compatible = "rockchip,rk3188-div-con";
						rockchip,bits = <0 5>;
						clocks = <&clk_rga>;
						clock-output-names = "clk_rga";
						rockchip,div-type = <CLK_DIVIDER_PLUS_ONE>;
						#clock-cells = <0>;
						rockchip,clkops-idx = <CLKOPS_RATE_MUX_DIV>;
						rockchip,flags = <CLK_SET_RATE_PARENT_IN_ORDER>;
					};

					/* 5 reserved */

					clk_rga: clk_rga_mux {
						compatible = "rockchip,rk3188-mux-con";
						rockchip,bits = <6 2>;
						clocks = <&clk_cpll>, <&clk_gpll>, <&dummy>, <&dummy>;
						clock-output-names = "clk_rga";
						#clock-cells = <0>;
						#clock-init-cells = <1>;
					};

					aclk_rga_div: aclk_rga_div {
						compatible = "rockchip,rk3188-div-con";
						rockchip,bits = <8 5>;
						clocks = <&aclk_rga>;
						clock-output-names = "aclk_rga";
						rockchip,div-type = <CLK_DIVIDER_PLUS_ONE>;
						#clock-cells = <0>;
						rockchip,clkops-idx = <CLKOPS_RATE_MUX_DIV>;
						rockchip,flags = <CLK_SET_RATE_PARENT_IN_ORDER>;
					};

					/* 13 reserved */

					aclk_rga: aclk_rga_mux {
						compatible = "rockchip,rk3188-mux-con";
						rockchip,bits = <14 2>;
						clocks = <&clk_cpll>, <&clk_gpll>, <&dummy>, <&dummy>;
						clock-output-names = "aclk_rga";
						#clock-cells = <0>;
						#clock-init-cells = <1>;
					};
				};

				clk_sel_con37: sel-con@0194 {
					compatible = "rockchip,rk3188-selcon";
					reg = <0x0194 0x4>;
					#address-cells = <1>;
					#size-cells = <1>;

					aclk_vio_div: aclk_vio_div {
						compatible = "rockchip,rk3188-div-con";
						rockchip,bits = <0 5>;
						clocks = <&aclk_vio>;
						clock-output-names = "aclk_vio";
						rockchip,div-type = <CLK_DIVIDER_PLUS_ONE>;
						#clock-cells = <0>;
						rockchip,clkops-idx = <CLKOPS_RATE_MUX_DIV>;
						rockchip,flags = <CLK_SET_RATE_PARENT_IN_ORDER>;
					};

					/* 5 reserved */

					aclk_vio: aclk_vio_mux {
						compatible = "rockchip,rk3188-mux-con";
						rockchip,bits = <6 2>;
						clocks = <&clk_cpll>, <&clk_gpll>, <&dummy>, <&usb480m>;
						clock-output-names = "aclk_vio";
						#clock-cells = <0>;
						#clock-init-cells = <1>;
					};

					hclk_vio: hclk_vio_div {
						compatible = "rockchip,rk3188-div-con";
						rockchip,bits = <8 5>;
						clocks = <&aclk_vio_div>;
						clock-output-names = "hclk_vio";
						rockchip,div-type = <CLK_DIVIDER_PLUS_ONE>;
						#clock-cells = <0>;
						#clock-init-cells = <1>;
					};

					/* 15:13 reserved */

				};

				clk_sel_con38: sel-con@0198 {
					compatible = "rockchip,rk3188-selcon";
					reg = <0x0198 0x4>;
					#address-cells = <1>;
					#size-cells = <1>;

					/* 5:0 reserved */

					clk_rtc32k_div: clk_rtc32k_div {
						compatible = "rockchip,rk3188-div-con";
						rockchip,bits = <0 14>;
						clocks = <&clk_rtc32k>;
						clock-output-names = "clk_rtc32k";
						rockchip,div-type = <CLK_DIVIDER_PLUS_ONE>;
						#clock-cells = <0>;
						rockchip,clkops-idx = <CLKOPS_RATE_MUX_DIV>;
						rockchip,flags = <(CLK_SET_RATE_PARENT_IN_ORDER |
								  CLK_SET_RATE_NO_REPARENT)>;
					};

					clk_rtc32k: clk_rtc32k_mux {
						compatible = "rockchip,rk3188-mux-con";
						rockchip,bits = <14 2>;
						clocks = <&clk_cpll>, <&clk_gpll>, <&xin24m>, <&dummy>;
						clock-output-names = "clk_rtc32k";
						#clock-cells = <0>;
						#clock-init-cells = <1>;
					};
				};

				clk_sel_con39: sel-con@019c {
					compatible = "rockchip,rk3188-selcon";
					reg = <0x019c 0x4>;
					#address-cells = <1>;
					#size-cells = <1>;

					aclk_vop: aclk_vop_div {
						compatible = "rockchip,rk3188-div-con";
						rockchip,bits = <0 5>;
						clocks = <&aclk_vop_mux>;
						clock-output-names = "aclk_vop";
						rockchip,div-type = <CLK_DIVIDER_PLUS_ONE>;
						#clock-cells = <0>;
						#clock-init-cells = <1>;
						rockchip,clkops-idx = <CLKOPS_RATE_MUX_DIV>;
						rockchip,flags = <CLK_SET_RATE_PARENT_IN_ORDER>;
					};

					/* 5 reserved */

					aclk_vop_mux: aclk_vop_mux {
						compatible = "rockchip,rk3188-mux-con";
						rockchip,bits = <6 2>;
						clocks = <&clk_cpll>, <&clk_gpll>, <&dummy>, <&usb480m>;
						clock-output-names = "aclk_vop";
						#clock-cells = <0>;
						#clock-init-cells = <1>;
					};

					/* 15:8 reserved */
				};

				clk_sel_con40: sel-con@01a0 {
					compatible = "rockchip,rk3188-selcon";
					reg = <0x01a0 0x4>;
					#address-cells = <1>;
					#size-cells = <1>;

					dclk_vop_pll_mux: dclk_vop_pll_mux {
						compatible = "rockchip,rk3188-mux-con";
						rockchip,bits = <0 1>;
						clocks = <&clk_gpll>, <&clk_cpll>;
						clock-output-names = "dclk_vop_pll";
						#clock-cells = <0>;
						#clock-init-cells = <1>;
					};

					dclk_vop: dclk_vop_mux {
						compatible = "rockchip,rk3188-mux-con";
						rockchip,bits = <1 1>;
						clocks = <&hdmi_phy_clk>, <&dclk_vop_pll>;/*dclk_vop_pll*/
						clock-output-names = "dclk_vop";
						#clock-cells = <0>;
						#clock-init-cells = <1>;
						rockchip,flags = <CLK_SET_RATE_NO_REPARENT>;
					};

					/* 2 reserved */

					dclk_hdmiphy: dclk_hdmiphy_div {
						compatible = "rockchip,rk3188-div-con";
						rockchip,bits = <3 3>;
						clocks = <&dclk_vop_pll>;
						clock-output-names = "dclk_hdmiphy";
						rockchip,div-type = <CLK_DIVIDER_PLUS_ONE>;
						#clock-cells = <0>;
					};

					/* 7:6 reserved */

					dclk_vop_pll: dclk_vop_pll_div {
						compatible = "rockchip,rk3188-div-con";
						rockchip,bits = <8 8>;
						clocks = <&dclk_vop_pll_mux>;
						clock-output-names = "dclk_vop_pll";
						rockchip,div-type = <CLK_DIVIDER_PLUS_ONE>;
						#clock-cells = <0>;
						rockchip,clkops-idx = <CLKOPS_RATE_MUX_DIV>;
					};
				};

				clk_sel_con42: sel-con@01a8 {
					compatible = "rockchip,rk3188-selcon";
					reg = <0x01a8 0x4>;
					#address-cells = <1>;
					#size-cells = <1>;

					clk_cif_out_div: clk_cif_out_div {
						compatible = "rockchip,rk3188-div-con";
						rockchip,bits = <0 5>;
						clocks = <&clk_cif_out>;
						clock-output-names = "clk_cif_out";
						rockchip,div-type = <CLK_DIVIDER_PLUS_ONE>;
						#clock-cells = <0>;
						rockchip,clkops-idx = <CLKOPS_RATE_MUX_DIV>;
						rockchip,flags = <CLK_SET_RATE_PARENT_IN_ORDER>;
					};

					clk_cif_out: clk_cif_out_mux {
						compatible = "rockchip,rk3188-mux-con";
						rockchip,bits = <5 1>;
						clocks = <&clk_cif_pll>, <&clk_24m>;
						clock-output-names = "clk_cif_out";
						#clock-cells = <0>;
						#clock-init-cells = <1>;
					};

					/* 6 reserved */

					clk_cif_pll: clk_cif_pll_mux {
						compatible = "rockchip,rk3188-mux-con";
						rockchip,bits = <7 1>;
						clocks = <&clk_cpll>, <&clk_gpll>;
						clock-output-names = "clk_cif_pll";
						#clock-cells = <0>;
						#clock-init-cells = <1>;
					};

					/* 15:8 reserved */
				};

				clk_sel_con43: sel-con@01ac {
					compatible = "rockchip,rk3188-selcon";
					reg = <0x01ac 0x4>;
					#address-cells = <1>;
					#size-cells = <1>;

					clk_sdmmcext_div: clk_sdmmcext_div {
						compatible = "rockchip,rk3188-div-con";
						rockchip,bits = <0 8>;
						clocks = <&clk_sdmmcext>;
						clock-output-names = "clk_sdmmcext";
						rockchip,div-type = <CLK_DIVIDER_PLUS_ONE>;
						#clock-cells = <0>;
						rockchip,clkops-idx = <CLKOPS_RATE_MUX_DIV>;
						rockchip,flags = <CLK_SET_RATE_PARENT_IN_ORDER>;
					};

					clk_sdmmcext: clk_sdmmcext_mux {
						compatible = "rockchip,rk3188-mux-con";
						rockchip,bits = <8 2>;
						clocks = <&clk_cpll>, <&clk_gpll>, <&xin24m>, <&usb480m>;
						clock-output-names = "clk_sdmmcext";
						#clock-cells = <0>;
						#clock-init-cells = <1>;
					};

					/* 15:10 reserved */
				};

				clk_sel_con44: sel-con@01b0 {
					compatible = "rockchip,rk3188-selcon";
					reg = <0x01b0 0x4>;
					#address-cells = <1>;
					#size-cells = <1>;

					clk_gpu_div: clk_gpu_div {
						compatible = "rockchip,rk3188-div-con";
						rockchip,bits = <0 5>;
						clocks = <&clk_gpu>;
						clock-output-names = "clk_gpu";
						rockchip,div-type = <CLK_DIVIDER_PLUS_ONE>;
						#clock-cells = <0>;
						rockchip,clkops-idx = <CLKOPS_RATE_MUX_DIV>;
						rockchip,flags = <CLK_SET_RATE_PARENT_IN_ORDER>;
					};

					/* 5 reserved */

					clk_gpu: clk_gpu_mux {
						compatible = "rockchip,rk3188-mux-con";
						rockchip,bits = <6 2>;
						clocks = <&clk_cpll>, <&clk_gpll>, <&dummy>, <&usb480m>;
						clock-output-names = "clk_gpu";
						#clock-cells = <0>;
						#clock-init-cells = <1>;
					};

					/* 15:8 reserved */
				};

				clk_sel_con45: sel-con@01b4 {
					compatible = "rockchip,rk3188-selcon";
					reg = <0x01b4 0x4>;
					#address-cells = <1>;
					#size-cells = <1>;

					clk_u3otg_ref_div: clk_u3otg_ref_div {
						compatible = "rockchip,rk3188-div-con";
						rockchip,bits = <0 7>;
						clocks = <&clk_u3otg_ref>;
						clock-output-names = "clk_u3otg_ref";
						rockchip,div-type = <CLK_DIVIDER_PLUS_ONE>;
						#clock-cells = <0>;
						rockchip,clkops-idx = <CLKOPS_RATE_MUX_DIV>;
						rockchip,flags = <CLK_SET_RATE_PARENT_IN_ORDER>;
					};

					clk_u3otg_ref: clk_u3otg_ref_mux {
						compatible = "rockchip,rk3188-mux-con";
						rockchip,bits = <7 1>;
						clocks = <&clk_cpll>, <&clk_gpll>;
						clock-output-names = "clk_u3otg_ref";
						#clock-cells = <0>;
						#clock-init-cells = <1>;
					};

					clk_usb3otg_ref: clk_usb3otg_ref_mux {
						compatible = "rockchip,rk3188-mux-con";
						rockchip,bits = <8 1>;
						clocks = <&xin24m>, <&clk_u3otg_ref_div>;
						clock-output-names = "clk_usb3otg_ref";
						#clock-cells = <0>;
						#clock-init-cells = <1>;
					};

					/* 15:9 reserved */
				};

				clk_sel_con48: sel-con@01c0 {
					compatible = "rockchip,rk3188-selcon";
					reg = <0x01c0 0x4>;
					#address-cells = <1>;
					#size-cells = <1>;

					aclk_rkvdec_div: aclk_rkvdec_div {
						compatible = "rockchip,rk3188-div-con";
						rockchip,bits = <0 5>;
						clocks = <&aclk_rkvdec>;
						clock-output-names = "aclk_rkvdec";
						rockchip,div-type = <CLK_DIVIDER_PLUS_ONE>;
						#clock-cells = <0>;
						#clock-init-cells = <1>;
						rockchip,clkops-idx = <CLKOPS_RATE_MUX_DIV>;
						rockchip,flags = <CLK_SET_RATE_PARENT_IN_ORDER>;
					};

					/* 5 reserved */

					aclk_rkvdec: aclk_rkvdec_mux {
						compatible = "rockchip,rk3188-mux-con";
						rockchip,bits = <6 2>;
						clocks = <&clk_cpll>, <&clk_gpll>, <&dummy>, <&usb480m>;
						clock-output-names = "aclk_rkvdec";
						#clock-cells = <0>;
						#clock-init-cells = <1>;
					};

					clk_vdec_cabac_div: clk_vdec_cabac_div {
						compatible = "rockchip,rk3188-div-con";
						rockchip,bits = <8 5>;
						clocks = <&clk_vdec_cabac>;
						clock-output-names = "clk_vdec_cabac";
						rockchip,div-type = <CLK_DIVIDER_PLUS_ONE>;
						#clock-cells = <0>;
						#clock-init-cells = <1>;
						rockchip,clkops-idx = <CLKOPS_RATE_MUX_DIV>;
						rockchip,flags = <CLK_SET_RATE_PARENT_IN_ORDER>;
					};

					/* 13 reserved */

					clk_vdec_cabac: clk_vdec_cabac_mux {
						compatible = "rockchip,rk3188-mux-con";
						rockchip,bits = <14 2>;
						clocks = <&clk_cpll>, <&clk_gpll>, <&dummy>, <&usb480m>;
						clock-output-names = "clk_vdec_cabac";
						#clock-cells = <0>;
						#clock-init-cells = <1>;
					};
				};

				clk_sel_con49: sel-con@01c4 {
					compatible = "rockchip,rk3188-selcon";
					reg = <0x01c4 0x4>;
					#address-cells = <1>;
					#size-cells = <1>;

					clk_vdec_core_div: clk_vdec_core_div {
						compatible = "rockchip,rk3188-div-con";
						rockchip,bits = <0 5>;
						clocks = <&clk_vdec_core>;
						clock-output-names = "clk_vdec_core";
						rockchip,div-type = <CLK_DIVIDER_PLUS_ONE>;
						#clock-cells = <0>;
						#clock-init-cells = <1>;
						rockchip,clkops-idx = <CLKOPS_RATE_MUX_DIV>;
						rockchip,flags = <CLK_SET_RATE_PARENT_IN_ORDER>;
					};

					/* 5 reserved */

					clk_vdec_core: clk_vdec_core_mux {
						compatible = "rockchip,rk3188-mux-con";
						rockchip,bits = <6 2>;
						clocks = <&clk_cpll>, <&clk_gpll>, <&dummy>, <&usb480m>;
						clock-output-names = "clk_vdec_core";
						#clock-cells = <0>;
						#clock-init-cells = <1>;
					};

					/* 15:8 reserved */
				};

				clk_sel_con50: sel-con@01c8 {
					compatible = "rockchip,rk3188-selcon";
					reg = <0x01c8 0x4>;
					#address-cells = <1>;
					#size-cells = <1>;

					aclk_vpu_div: aclk_vpu_div {
						compatible = "rockchip,rk3188-div-con";
						rockchip,bits = <0 5>;
						clocks = <&aclk_vpu>;
						clock-output-names = "aclk_vpu";
						rockchip,div-type = <CLK_DIVIDER_PLUS_ONE>;
						#clock-cells = <0>;
						#clock-init-cells = <1>;
						rockchip,clkops-idx = <CLKOPS_RATE_MUX_DIV>;
						rockchip,flags = <CLK_SET_RATE_PARENT_IN_ORDER>;
					};

					/* 5 reserved */

					aclk_vpu: aclk_vpu_mux {
						compatible = "rockchip,rk3188-mux-con";
						rockchip,bits = <6 2>;
						clocks = <&clk_cpll>, <&clk_gpll>, <&dummy>, <&usb480m>;
						clock-output-names = "aclk_vpu";
						#clock-cells = <0>;
						#clock-init-cells = <1>;
					};

					/* 15:8 reserved */
				};

				clk_sel_con51: sel-con@01cc {
					compatible = "rockchip,rk3188-selcon";
					reg = <0x01cc 0x4>;
					#address-cells = <1>;
					#size-cells = <1>;

					aclk_rkvenc_div: aclk_rkvenc_div {
						compatible = "rockchip,rk3188-div-con";
						rockchip,bits = <0 5>;
						clocks = <&aclk_rkvenc>;
						clock-output-names = "aclk_rkvenc";
						rockchip,div-type = <CLK_DIVIDER_PLUS_ONE>;
						#clock-cells = <0>;
						#clock-init-cells = <1>;
						rockchip,clkops-idx = <CLKOPS_RATE_MUX_DIV>;
						rockchip,flags = <CLK_SET_RATE_PARENT_IN_ORDER>;
					};

					/* 5 reserved */

					aclk_rkvenc: aclk_rkvenc_mux {
						compatible = "rockchip,rk3188-mux-con";
						rockchip,bits = <6 2>;
						clocks = <&clk_cpll>, <&clk_gpll>, <&dummy>, <&usb480m>;
						clock-output-names = "aclk_rkvenc";
						#clock-cells = <0>;
						#clock-init-cells = <1>;
					};

					clk_venc_core_div: clk_venc_core_div {
						compatible = "rockchip,rk3188-div-con";
						rockchip,bits = <8 5>;
						clocks = <&clk_venc_core>;
						clock-output-names = "clk_venc_core";
						rockchip,div-type = <CLK_DIVIDER_PLUS_ONE>;
						#clock-cells = <0>;
						#clock-init-cells = <1>;
						rockchip,clkops-idx = <CLKOPS_RATE_MUX_DIV>;
						rockchip,flags = <CLK_SET_RATE_PARENT_IN_ORDER>;
					};

					/* 13 reserved */

					clk_venc_core: clk_venc_core_mux {
						compatible = "rockchip,rk3188-mux-con";
						rockchip,bits = <14 2>;
						clocks = <&clk_cpll>, <&clk_gpll>, <&dummy>, <&usb480m>;
						clock-output-names = "clk_venc_core";
						#clock-cells = <0>;
						#clock-init-cells = <1>;
					};
				};

				clk_sel_con52: sel-con@01d0 {
					compatible = "rockchip,rk3188-selcon";
					reg = <0x01d0 0x4>;
					#address-cells = <1>;
					#size-cells = <1>;

					clk_wifi_div: clk_wifi_div {
						compatible = "rockchip,rk3188-div-con";
						rockchip,bits = <0 6>;
						clocks = <&clk_wifi>;
						clock-output-names = "clk_wifi";
						rockchip,div-type = <CLK_DIVIDER_PLUS_ONE>;
						#clock-cells = <0>;
						rockchip,clkops-idx = <CLKOPS_RATE_MUX_DIV>;
						rockchip,flags = <CLK_SET_RATE_PARENT_IN_ORDER>;
					};

					clk_wifi: clk_wifi_mux {
						compatible = "rockchip,rk3188-mux-con";
						rockchip,bits = <6 2>;
						clocks = <&clk_cpll>, <&clk_gpll>, <&usb480m>, <&xin24m>;
						clock-output-names = "clk_wifi";
						#clock-cells = <0>;
						#clock-init-cells = <1>;
					};

					clk_venc_dsp_div: clk_venc_dsp_div {
						compatible = "rockchip,rk3188-div-con";
						rockchip,bits = <8 5>;
						clocks = <&clk_venc_dsp>;
						clock-output-names = "clk_venc_dsp";
						rockchip,div-type = <CLK_DIVIDER_PLUS_ONE>;
						#clock-cells = <0>;
						#clock-init-cells = <1>;
						rockchip,clkops-idx = <CLKOPS_RATE_MUX_DIV>;
						rockchip,flags = <CLK_SET_RATE_PARENT_IN_ORDER>;
					};

					/* 13 reserved */

					clk_venc_dsp: clk_venc_dsp_mux {
						compatible = "rockchip,rk3188-mux-con";
						rockchip,bits = <14 2>;
						clocks = <&clk_cpll>, <&clk_gpll>, <&dummy>, <&usb480m>;
						clock-output-names = "clk_venc_dsp";
						#clock-cells = <0>;
						#clock-init-cells = <1>;
					};
				};

				clk_sel_con53: sel-con@0084 {
					compatible = "rockchip,rk3188-selcon";
					reg = <0x0084 0x4>;
					#address-cells = <1>;
					#size-cells = <1>;

					/* 7:0 reserved */

					 testclk: testclk_mux {
						compatible = "rockchip,rk3188-mux-con";
						rockchip,bits = <8 4>;
						clocks = <&clk_wifi>, <&dummy>, <&clk_core>, <&clk_ddr>, <&aclk_rkvdec>, <&aclk_rkvenc>,
								<&aclk_vpu>, <&aclk_rga>, <&aclk_vio>, <&aclk_vop>, <&clk_gpu>, <&aclk_bus>,
								<&aclk_peri>, <&aclk_gmac>, <&dclk_vop>, <&clk_pdm>, <&clk_rga>, <&clk_vdec_core>,
								<&clk_venc_core>, <&clk_tsp>, <&dummy>, <&dummy>, <&dummy>, <&xin24m>;
						clock-output-names = "testclk";
						#clock-cells = <0>;
						#clock-init-cells = <1>;
					};

					hdmi_phy_clk: hdmi_phy_clk_mux {
						compatible = "rockchip,rk3188-mux-con";
						rockchip,bits = <13 1>;
						clocks = <&hdmiphy_out>, <&xin24m>;
						clock-output-names = "hdmi_phy_clk";
						#clock-cells = <0>;
						#clock-init-cells = <1>;
					};

					/* 14 reserved */

					usb480m: usb480m_mux {
						compatible = "rockchip,rk3188-mux-con";
						rockchip,bits = <15 1>;
						clocks = <&usbphy_480m>, <&xin24m>;
						clock-output-names = "usb480m";
						#clock-cells = <0>;
						rockchip,clkops-idx =
							<CLKOPS_RATE_RK3288_USB480M>;
						#clock-init-cells = <1>;
					};
				};
			};

			/* Gate control regs */
			clk_gate_cons {
				compatible = "rockchip,rk-gate-cons";
				#address-cells = <1>;
				#size-cells = <1>;
				ranges;

				clk_gates0: gate-clk@0200 {
					compatible = "rockchip,rk3188-gate-clk";
					reg = <0x0200 0x4>;
					clocks =
					<&dummy>,	<&dummy>,
					<&dummy>,	<&dummy>,

					<&dummy>,	<&dummy>,
					<&dummy>,	<&dummy>,

					<&dummy>,	<&testclk>,
					<&clk_wifi>,	<&clk_rtc32k>,

					<&dummy>,	<&dummy>,
					<&dummy>,	<&dummy>;

					clock-output-names =
					"reserved",	"reserved",
					"reserved",	"reserved",

					"reserved",	"reserved",
					"reserved",	"reserved",

					"reserved",	"testclk",
					"clk_wifi",	"clk_rtc32k",

					"reserved",	"reserved",
					"reserved",	"reserved";

					#clock-cells = <1>;
				};

				clk_gates1: gate-clk@0204 {
					compatible = "rockchip,rk3188-gate-clk";
					reg = <0x0204 0x4>;
					clocks =
					<&dummy>,	<&clk_i2s0_pll>,
					<&i2s0_frac>,	<&clk_i2s0>,

					<&clk_i2s1_pll>,	<&i2s1_frac>,
					<&clk_i2s1>,	<&clk_i2s1_out>,

					<&clk_uart0_pll>,	<&uart0_frac>,
					<&clk_uart1_pll>,	<&uart1_frac>,

					<&clk_spdif_pll>,	<&spdif_frac>,
					<&clk_uart0_pll>,	<&uart0_frac>;

					clock-output-names =
					"reserved",	"clk_i2s0_pll",
					"i2s0_frac",	"clk_i2s0",

					"clk_i2s1_pll",	"i2s1_frac",
					"clk_i2s1",	"clk_i2s1_out",

					"clk_i2s2_pll",	"i2s2_frac",
					"clk_i2s2",	"clk_i2s2_out",

					"clk_spdif_pll",	"spdif_frac",
					"clk_uart0_pll",	"uart0_frac";

					#clock-cells = <1>;
				};

				clk_gates2: gate-clk@0208 {
					compatible = "rockchip,rk3188-gate-clk";
					reg = <0x0208 0x4>;
					clocks =
					<&clk_uart1_pll>,	<&uart1_frac>,
					<&clk_uart2_pll>,	<&uart2_frac>,

					<&clk_crypto>,	<&clk_tsp>,
					<&clk_tsadc>,	<&clk_spi>,

					<&clk_pwm>,	<&clk_i2c0>,
					<&clk_i2c1>,	<&clk_i2c2>,

					<&clk_i2c3>,	<&clk_efuse>,
					<&clk_saradc>,	<&clk_pdm>;

					clock-output-names =
					"clk_uart1_pll",	"uart1_frac",
					"clk_uart2_pll",	"uart2_frac",

					"clk_crypto",	"clk_tsp",
					"clk_tsadc",	"clk_spi",

					"clk_pwm",	"clk_i2c0",
					"clk_i2c1",	"clk_i2c2",

					"clk_i2c3",	"clk_efuse",
					"clk_saradc",	"clk_pdm";

					#clock-cells = <1>;
				};

				clk_gates3: gate-clk@020c {
					compatible = "rockchip,rk3188-gate-clk";
					reg = <0x020c 0x4>;
					clocks =
					<&dummy>,	<&dummy>,
					<&aclk_gmac>,	<&dummy>,

					<&dummy>,	<&clk_mac2io_out>,
					<&dummy>,	<&dummy>,

					<&clk_otp>,	<&dummy>,
					<&dummy>,	<&dummy>,

					<&dummy>,	<&dummy>,
					<&dummy>,	<&dummy>;

					clock-output-names =
					"reserved",	"reserved",
					"aclk_gmac",	"reserved",

					"reserved",	"clk_mac2io_out",
					"reserved",	"reserved",

					"clk_otp",	"reserved",
					"reserved",	"reserved",

					"reserved",	"reserved",
					"reserved",	"reserved";

					#clock-cells = <1>;
				};

				clk_gates4: gate-clk@0210 {
					compatible = "rockchip,rk3188-gate-clk";
					reg = <0x0210 0x4>;
					clocks =
					<&dummy>,	<&dummy>,
					<&dummy>,	<&clk_sdmmc>,

					<&clk_sdio>,	<&clk_emmc>,
					<&dummy>,	<&xin24m>,

					<&clk_usb3otg0_s>,	<&clk_u3otg_ref>,
					<&clk_sdmmcext>,	<&dummy>,

					<&dummy>,	<&dummy>,
					<&dummy>,	<&dummy>;

					clock-output-names =
					"reserved",	"reserved",
					"reserved",	"clk_sdmmc",

					"clk_sdio",	"clk_emmc",
					"reserved",	"usb3otg_ref",

					"clk_usb3otg0_s",	"clk_u3otg_ref",
					"clk_sdmmcext",	"reserved",

					"reserved",	"reserved",
					"reserved",	"reserved";

					#clock-cells = <1>;
				};

				clk_gates5: gate-clk@0214 {
					compatible = "rockchip,rk3188-gate-clk";
					reg = <0x0214 0x4>;
					clocks =
					<&aclk_rga>,	<&clk_rga>,
					<&aclk_vio>,	<&clk_cif_out>,

					<&xin24m>,	<&aclk_vop>,
					<&dclk_vop_pll>,	<&dummy>,

					<&dummy>,	<&dummy>,
					<&dummy>,	<&dummy>,

					<&dummy>,	<&dummy>,
					<&dummy>,	<&dummy>;

					clock-output-names =
					"aclk_rga",	"clk_rga",
					"aclk_vio",	"clk_cif_out",

					"clk_hdmi_sfc",	"aclk_vop",
					"dclk_vop_pll",	"reserved",

					"reserved",	"reserved",
					"reserved",	"reserved",

					"reserved",	"reserved",
					"reserved",	"reserved";

					#clock-cells = <1>;
				};

				clk_gates6: gate-clk@0218 {
					compatible = "rockchip,rk3188-gate-clk";
					reg = <0x0218 0x4>;
					clocks =
					<&aclk_rkvdec>,	<&clk_vdec_cabac>,
					<&clk_vdec_core>,	<&aclk_rkvenc>,

					<&clk_venc_core>,	<&aclk_vpu>,
					<&clk_gpu>,	<&clk_venc_dsp>,

					<&dummy>,	<&dummy>,
					<&dummy>,	<&dummy>,

					<&dummy>,	<&dummy>,
					<&dummy>,	<&dummy>;

					clock-output-names =
					"aclk_rkvdec",	"clk_vdec_cabac",
					"clk_vdec_core",	"aclk_rkvenc",

					"clk_venc_core",	"aclk_vpu",
					"clk_gpu",	"clk_venc_dsp",

					"reserved",	"reserved",
					"reserved",	"reserved",

					"reserved",	"reserved",
					"reserved",	"reserved";

					#clock-cells = <1>;
				};

				clk_gates7: gate-clk@021c {
					compatible = "rockchip,rk3188-gate-clk";
					reg = <0x021c 0x4>;
					clocks =
					<&aclk_core>,	<&pclk_dbg>,
					<&jtag_clkin>,	<&dummy>,

					<&pclk_ddr>,	<&dummy>,
					<&dummy>,	<&dummy>,

					<&dummy>,	<&dummy>,
					<&dummy>,	<&dummy>,

					<&dummy>,	<&dummy>,
					<&dummy>,	<&dummy>;

					clock-output-names =
					"aclk_core",	"pclk_dbg",
					"clk_jtag",	"reserved",

					"pclk_ddr",	"reserved",
					"reserved",	"reserved",

					"reserved",	"reserved",
					"reserved",	"reserved",

					"reserved",	"reserved",
					"reserved",	"reserved";

					#clock-cells = <1>;
				};

				clk_gates8: gate-clk@0220 {
					compatible = "rockchip,rk3188-gate-clk";
					reg = <0x0220 0x4>;
					clocks =
					<&aclk_bus>,	<&aclk_bus>,
					<&dummy>,	<&pclk_bus>,

					<&pclk_bus>,	<&xin24m>,
					<&xin24m>,	<&xin24m>,

					<&xin24m>,	<&xin24m>,
					<&xin24m>,	<&dummy>,

					<&dummy>,	<&dummy>,
					<&dummy>,	<&dummy>;

					clock-output-names =
					"aclk_bus",	"hclk_bus",
					"reserved",	"pclk_bus",

					"pclk_phy",	"clk_timer0",
					"clk_timer1",	"clk_timer2",

					"clk_timer3",	"clk_timer4",
					"clk_timer5",	"reserved",

					"reserved",	"reserved",
					"reserved",	"reserved";

					#clock-cells = <1>;
				};

				clk_gates9: gate-clk@0224 {
					compatible = "rockchip,rk3188-gate-clk";
					reg = <0x0224 0x4>;
					clocks =
					<&aclk_gmac>,	<&clk_gmac2phy>,
					<&clk_mac2phy>,	<&clk_gmac2phy>,

					<&clk_gmac2io>,	<&clk_gmac2io>,
					<&clk_gmac2io>,	<&clk_gmac2io>,

					<&dummy>,	<&dummy>,
					<&dummy>,	<&dummy>,

					<&dummy>,	<&dummy>,
					<&dummy>,	<&dummy>;

					clock-output-names =
					"pclk_gmac",	"clk_mac2phy_rx",
					"clk_mac2phy_out",	"clk_mac2phy_ref",

					"clk_mac2io_rx",	"clk_mac2io_tx",
					"clk_mac2io_rout",	"clk_mac2io_ref",

					"reserved",	"reserved",
					"reserved",	"reserved",

					"reserved",	"reserved",
					"reserved",	"reserved";

					#clock-cells = <1>;
				};

				clk_gates10: gate-clk@0228 {
					compatible = "rockchip,rk3188-gate-clk";
					reg = <0x0228 0x4>;
					clocks =
					<&aclk_peri>,	<&aclk_peri>,
					<&aclk_peri>,	<&dummy>,

					<&dummy>,	<&dummy>,
					<&dummy>,	<&dummy>,

					<&dummy>,	<&dummy>,
					<&dummy>,	<&dummy>,

					<&dummy>,	<&dummy>,
					<&dummy>,	<&dummy>;

					clock-output-names =
					"aclk_peri",	"hclk_peri",
					"pclk_peri",	"reserved",

					"reserved",	"reserved",
					"reserved",	"reserved",

					"reserved",	"reserved",
					"reserved",	"reserved",

					"reserved",	"reserved",
					"reserved",	"reserved";

					#clock-cells = <1>;
				};

				clk_gates11: gate-clk@022c {
					compatible = "rockchip,rk3188-gate-clk";
					reg = <0x022c 0x4>;
					clocks =
					<&hclk_rkvdec>,	<&dummy>,
					<&dummy>,	<&dummy>,

					<&hclk_rkvenc>,	<&dummy>,
					<&dummy>,	<&dummy>,

					<&hclk_vpu>,	<&dummy>,
					<&dummy>,	<&dummy>,

					<&dummy>,	<&dummy>,
					<&dummy>,	<&dummy>;

					clock-output-names =
					"hclk_rkvdec",	"reserved",
					"reserved",	"reserved",

					"hclk_rkvenc",	"reserved",
					"reserved",	"reserved",

					"hclk_vpu",	"reserved",
					"reserved",	"reserved",

					"reserved",	"reserved",
					"reserved",	"reserved";

					#clock-cells = <1>;
				};

				clk_gates12: gate-clk@0230 {
					compatible = "rockchip,rk3188-gate-clk";
					reg = <0x0230 0x4>;
					clocks =
					<&dummy>,	<&dummy>,
					<&dummy>,	<&dummy>,

					<&dummy>,	<&dummy>,
					<&dummy>,	<&dummy>,

					<&dummy>,	<&dummy>,
					<&dummy>,	<&dummy>,

					<&dummy>,	<&dummy>,
					<&dummy>,	<&dummy>;

					clock-output-names =
					"reserved",	"reserved",
					"reserved",	"reserved",

					"reserved",	"reserved",
					"reserved",	"reserved",

					"reserved",	"reserved",
					"reserved",	"reserved",

					"reserved",	"reserved",
					"reserved",	"reserved";

					#clock-cells = <1>;
				};

				clk_gates13: gate-clk@0234 {
					compatible = "rockchip,rk3188-gate-clk";
					reg = <0x0234 0x4>;
					clocks =
					<&aclk_core>,	<&aclk_core>,
					<&dummy>,	<&dummy>,

					<&dummy>,	<&dummy>,
					<&dummy>,	<&dummy>,

					<&dummy>,	<&dummy>,
					<&dummy>,	<&dummy>,

					<&dummy>,	<&dummy>,
					<&dummy>,	<&dummy>;

					clock-output-names =
					"aclk_core_noc",	"aclk_gic",
					"reserved",	"reserved",

					"reserved",	"reserved",
					"reserved",	"reserved",

					"reserved",	"reserved",
					"reserved",	"reserved",

					"reserved",	"reserved",
					"reserved",	"reserved";

					#clock-cells = <1>;
				};

				clk_gates14: gate-clk@0238 {
					compatible = "rockchip,rk3188-gate-clk";
					reg = <0x0238 0x4>;
					clocks =
					<&dummy>,	<&dummy>,
					<&dummy>,	<&dummy>,

					<&dummy>,	<&dummy>,
					<&dummy>,	<&dummy>,

					<&dummy>,	<&dummy>,
					<&dummy>,	<&dummy>,

					<&dummy>,	<&dummy>,
					<&dummy>,	<&dummy>;

					clock-output-names =
					"reserved",	"clk_gpu_niu",
					"reserved",	"reserved",

					"reserved",	"reserved",
					"reserved",	"reserved",

					"reserved",	"reserved",
					"reserved",	"reserved",

					"reserved",	"reserved",
					"reserved",	"reserved";

					#clock-cells = <1>;
				};

				clk_gates15: gate-clk@023c {
					compatible = "rockchip,rk3188-gate-clk";
					reg = <0x023c 0x4>;
					clocks =
					<&aclk_bus>,	<&aclk_bus>,
					<&hclk_bus>,	<&hclk_bus>,

					<&hclk_bus>,	<&hclk_bus>,
					<&hclk_bus>,	<&hclk_bus>,

					<&hclk_bus>,	<&pclk_bus>,
					<&pclk_bus>,	<&aclk_bus>,

					<&dummy>,	<&dummy>,
					<&dummy>,	<&dummy>;

					clock-output-names =
					"aclk_intmem",	"aclk_dmac",
					"hclk_rom",	"hclk_i2s0_8ch",

					"hclk_i2s1_8ch",	"hclk_i2s2_2ch",
					"hclk_spdif_8ch",	"mclk_crypto",

					"sclk_crypto",	"pclk_efuse_1024",
					"pclk_i2c0",	"aclk_dcf",

					"aclk_bus_niu",	"hclk_bus_niu",
					"pclk_bus_niu",	"pclk_phy_niu";

					#clock-cells = <1>;
				};

				clk_gates16: gate-clk@0240 {
					compatible = "rockchip,rk3188-gate-clk";
					reg = <0x0240 0x4>;
					clocks =
					<&pclk_bus>,	<&pclk_bus>,
					<&pclk_bus>,	<&pclk_bus>,

					<&pclk_bus>,	<&pclk_bus>,
					<&pclk_bus>,	<&pclk_bus>,

					<&pclk_bus>,	<&pclk_bus>,
					<&pclk_bus>,	<&pclk_bus>,

					<&pclk_bus>,	<&pclk_bus>,
					<&pclk_bus>,	<&pclk_bus>;

					clock-output-names =
					"pclk_i2c1",	"pclk_i2c2",
					"pclk_i2c3",	"pclk_timer0",

					"pclk_stimer",	"pclk_spi",
					"pclk_pwm",	"pclk_gpio0",

					"pclk_gpio1",	"pclk_gpio2",
					"pclk_gpio3",	"pclk_uart0",

					"pclk_uart1",	"pclk_uart2",
					"pclk_tsadc",	"pclk_dcf";

					#clock-cells = <1>;
				};

				clk_gates17: gate-clk@0244 {
					compatible = "rockchip,rk3188-gate-clk";
					reg = <0x0244 0x4>;
					clocks =
					<&pclk_bus>,	<&dummy>,
					<&clk_gates8 4>,	<&clk_gates8 4>,

					<&pclk_bus>,	<&clk_gates8 4>,
					<&pclk_bus>,	<&clk_gates8 4>,

					<&clk_gates8 4>,	<&dummy>,
					<&pclk_bus>,	<&hclk_bus>,

					<&aclk_bus>,	<&ext_gpio3a2>,
					<&clk_gates8 4>,	<&pclk_bus>;

					clock-output-names =
					"pclk_grf",	"reserved",
					"pclk_usb3grf",	"pclk_ddrphy",

					"pclk_cru",	"pclk_acodecphy",
					"pclk_sgrf",	"pclk_hdmiphy",

					"pclk_vdacphy",	"reserved",
					"pclk_scr",	"hclk_tsp",

					"aclk_tsp",	"clk_hsadc_tsp",
					"pclk_usb_grf",	"pclk_saradc";

					#clock-cells = <1>;
				};

				clk_gates18: gate-clk@0248 {
					compatible = "rockchip,rk3188-gate-clk";
					reg = <0x0248 0x4>;
					clocks =
					<&dummy>,	<&pclk_ddr>,
					<&pclk_ddr>,	<&pclk_ddr>,

					<&clk_ddr>,	<&clk_ddr>,
					<&clk_ddr>,	<&pclk_ddr>,

					<&dummy>,	<&pclk_ddr>,
					<&dummy>,	<&dummy>,

					<&dummy>,	<&dummy>,
					<&dummy>,	<&dummy>;

					clock-output-names =
					"reserved",	"pclk_ddrupctl",
					"pclk_ddr_msch",	"pclk_ddr_mon",

					"aclk_ddrupctl",	"clk_ddrupctl",
					"clk_ddrmsch",	"pclk_ddrstdby",

					"reserved",	"pclk_ddr_grf",
					"reserved",	"reserved",

					"reserved",	"reserved",
					"reserved",	"reserved";

					#clock-cells = <1>;
				};

				clk_gates19: gate-clk@024c {
					compatible = "rockchip,rk3188-gate-clk";
					reg = <0x024c 0x4>;
					clocks =
					<&hclk_peri>,	<&hclk_peri>,
					<&hclk_peri>,	<&dummy>,

					<&dummy>,	<&dummy>,
					<&hclk_peri>,	<&hclk_peri>,

					<&hclk_peri>,	<&hclk_peri>,
					<&dummy>,	<&dummy>,

					<&dummy>,	<&dummy>,
					<&aclk_peri>,	<&hclk_peri>;

					clock-output-names =
					"hclk_sdmmc",	"hclk_sdio",
					"hclk_emmc",	"reserved",

					"reserved",	"reserved",
					"hclk_host0",	"hclk_host0_arb",

					"hclk_otg",	"hclk_otg_pmu",
					"reserved",	"aclk_peri_niu",

					"hclk_peri_niu",	"pclk_peri_niu",
					"aclk_usb3otg",	"hclk_sdmmc_ext";

					#clock-cells = <1>;
				};

				clk_gates21: gate-clk@0254 {
					compatible = "rockchip,rk3188-gate-clk";
					reg = <0x0254 0x4>;
					clocks =
					<&dummy>,	<&dummy>,
					<&dummy>,	<&hclk_vio>,

					<&dummy>,	<&dummy>,
					<&aclk_vio>,	<&hclk_vio>,

					<&aclk_vio>,	<&hclk_vio>,
					<&aclk_rga>,	<&hclk_vio>,

					<&hclk_vio>,	<&hclk_vio>,
					<&hclk_vio>,	<&aclk_vio>;

					clock-output-names =
					"reserved",	"reserved",
					"dummy",	"hclk_vop",

					"aclk_vop_noc",	"hclk_vop_niu",
					"aclk_iep",	"hclk_iep",

					"aclk_cif",	"hclk_cif",
					"p_aclk_rga",	"hclk_rga",

					"hclk_ahb1tom",	"pclk_h2p",
					"hclk_h2p",	"aclk_hdcp";

					#clock-cells = <1>;
				};

				clk_gates22: gate-clk@0258 {
					compatible = "rockchip,rk3188-gate-clk";
					reg = <0x0258 0x4>;
					clocks =
					<&hclk_vio>,	<&dummy>,
					<&dummy>,	<&aclk_rga>,

					<&hclk_vio>,	<&hclk_vio>,
					<&dummy>,	<&dummy>,

					<&dummy>,	<&dummy>,
					<&dummy>,	<&dummy>,

					<&dummy>,	<&dummy>,
					<&dummy>,	<&dummy>;

					clock-output-names =
					"hclk_hdcp_mmu",	"hclk_vio_noc",
					"aclk_vio_noc",	"aclk_rga_noc",

					"pclk_hdmi_ctrl",	"pclk_hdcp_ctrl",
					"reserved",	"reserved",

					"reserved",	"reserved",
					"reserved",	"reserved",

					"reserved",	"reserved",
					"reserved",	"reserved";

					#clock-cells = <1>;
				};

				clk_gates23: gate-clk@025c {
					compatible = "rockchip,rk3188-gate-clk";
					reg = <0x025c 0x4>;
					clocks =
					<&dummy>,	<&dummy>,
					<&dummy>,	<&dummy>,

					<&dummy>,	<&dummy>,
					<&dummy>,	<&dummy>,

					<&dummy>,	<&dummy>,
					<&dummy>,	<&dummy>,

					<&dummy>,	<&dummy>,
					<&dummy>,	<&dummy>;

					clock-output-names =
					"reserved",	"reserved",
					"aclk_vpu_niu",	"hclk_vpu_niu",

					"reserved",	"reserved",
					"reserved",	"reserved",

					"reserved",	"reserved",
					"reserved",	"reserved",

					"reserved",	"reserved",
					"reserved",	"reserved";

					#clock-cells = <1>;
				};

				clk_gates24: gate-clk@0260 {
					compatible = "rockchip,rk3188-gate-clk";
					reg = <0x0260 0x4>;
					clocks =
					<&dummy>,	<&dummy>,
					<&dummy>,	<&dummy>,

					<&dummy>,	<&dummy>,
					<&dummy>,	<&dummy>,

					<&dummy>,	<&dummy>,
					<&dummy>,	<&dummy>,

					<&dummy>,	<&dummy>,
					<&dummy>,	<&dummy>;

					clock-output-names =
					"reserved",	"reserved",
					"aclk_rkvdec_niu",	"hclk_rkvdec_niu",

					"reserved",	"reserved",
					"reserved",	"reserved",

					"reserved",	"reserved",
					"reserved",	"reserved",

					"reserved",	"reserved",
					"reserved",	"reserved";

					#clock-cells = <1>;
				};

				clk_gates25: gate-clk@0264 {
					compatible = "rockchip,rk3188-gate-clk";
					reg = <0x0264 0x4>;
					clocks =
					<&dummy>,	<&dummy>,
					<&aclk_rkvenc>,	<&hclk_rkvenc>,

					<&aclk_rkvenc>,	<&hclk_rkvenc>,
					<&aclk_rkvenc>,	<&dummy>,

					<&dummy>,	<&dummy>,
					<&dummy>,	<&dummy>,

					<&dummy>,	<&dummy>,
					<&dummy>,	<&dummy>;

					clock-output-names =
					"aclk_rkvenc_niu",	"hclk_rkvenc_niu",
					"aclk_h265",	"pclk_h265",

					"aclk_h264",	"hclk_h264",
					"aclk_axi2sram",	"reserved",

					"reserved",	"reserved",
					"reserved",	"reserved",

					"reserved",	"reserved",
					"reserved",	"reserved";

					#clock-cells = <1>;
				};

				clk_gates26: gate-clk@0268 {
					compatible = "rockchip,rk3188-gate-clk";
					reg = <0x0268 0x4>;
					clocks =
					<&aclk_gmac>,	<&pclk_gmac>,
					<&aclk_gmac>,	<&pclk_gmac>,

					<&dummy>,	<&dummy>,
					<&dummy>,	<&dummy>,

					<&dummy>,	<&dummy>,
					<&dummy>,	<&dummy>,

					<&dummy>,	<&dummy>,
					<&dummy>,	<&dummy>;

					clock-output-names =
					"aclk_gmac2phy",	"pclk_gmac2phy",
					"aclk_gmac2io",	"pclk_gmac2io",

					"aclk_gmac_niu",	"pclk_gmac_niu",
					"reserved",	"reserved",

					"reserved",	"reserved",
					"reserved",	"reserved",

					"reserved",	"reserved",
					"reserved",	"reserved";

					#clock-cells = <1>;
				};

				clk_gates27: gate-clk@026c {
					compatible = "rockchip,rk3188-gate-clk";
					reg = <0x026c 0x4>;
					clocks =
					<&dummy>,	<&dummy>,
					<&dummy>,	<&dummy>,

					<&dummy>,	<&dummy>,
					<&dummy>,	<&dummy>,

					<&dummy>,	<&dummy>,
					<&dummy>,	<&dummy>,

					<&dummy>,	<&dummy>,
					<&dummy>,	<&dummy>;

					clock-output-names =
					"reserved",	"reserved",
					"reserved",	"reserved",

					"reserved",	"reserved",
					"reserved",	"reserved",

					"reserved",	"reserved",
					"reserved",	"reserved",

					"reserved",	"reserved",
					"reserved",	"reserved";

					#clock-cells = <1>;
				};

				clk_gates28: gate-clk@0270 {
					compatible = "rockchip,rk3188-gate-clk";
					reg = <0x0270 0x4>;
					clocks =
					<&hclk_bus>,	<&clk_gates8 4>,
					<&clk_gates8 4>,	<&pclk_bus>,

					<&pclk_bus>,	<&dummy>,
					<&dummy>,	<&dummy>,

					<&dummy>,	<&dummy>,
					<&dummy>,	<&dummy>,

					<&dummy>,	<&dummy>,
					<&dummy>,	<&pclk_bus>;

					clock-output-names =
					"hclk_pdm",	"p_usb3phy_otg",
					"p_usb3phy_pipe",	"pclk_pmu",

					"pclk_otp",	"reserved",
					"reserved",	"reserved",

					"reserved",	"reserved",
					"reserved",	"reserved",

					"reserved",	"reserved",
					"reserved",	"pclk_wdt";

					#clock-cells = <1>;
				};
			};
		};

		special_regs {
			compatible = "rockchip,rk-clock-special-regs";
			#address-cells = <2>;
			#size-cells = <2>;
			ranges;

			clk_gmac2io: clk_gmac2io_mux {
				compatible = "rockchip,rk3188-mux-con";
				reg = <0x0 0xff100904 0x0 0x4>;
				rockchip,bits = <10 1>;
				clocks = <&clk_mac2io>, <&gmac_clkin>;
				clock-output-names = "clk_gmac2io";
				#clock-cells = <0>;
				#clock-init-cells = <1>;
			};

			clk_gmac2phy: clk_gmac2phy_mux {
				compatible = "rockchip,rk3188-mux-con";
				reg = <0x0 0xff100908 0x0 0x4>;
				rockchip,bits = <10 1>;
				clocks = <&clk_mac2phy>, <&phy_50m_out>;
				clock-output-names = "clk_gmac2phy";
				#clock-cells = <0>;
				#clock-init-cells = <1>;
			};
		};
	};
};
